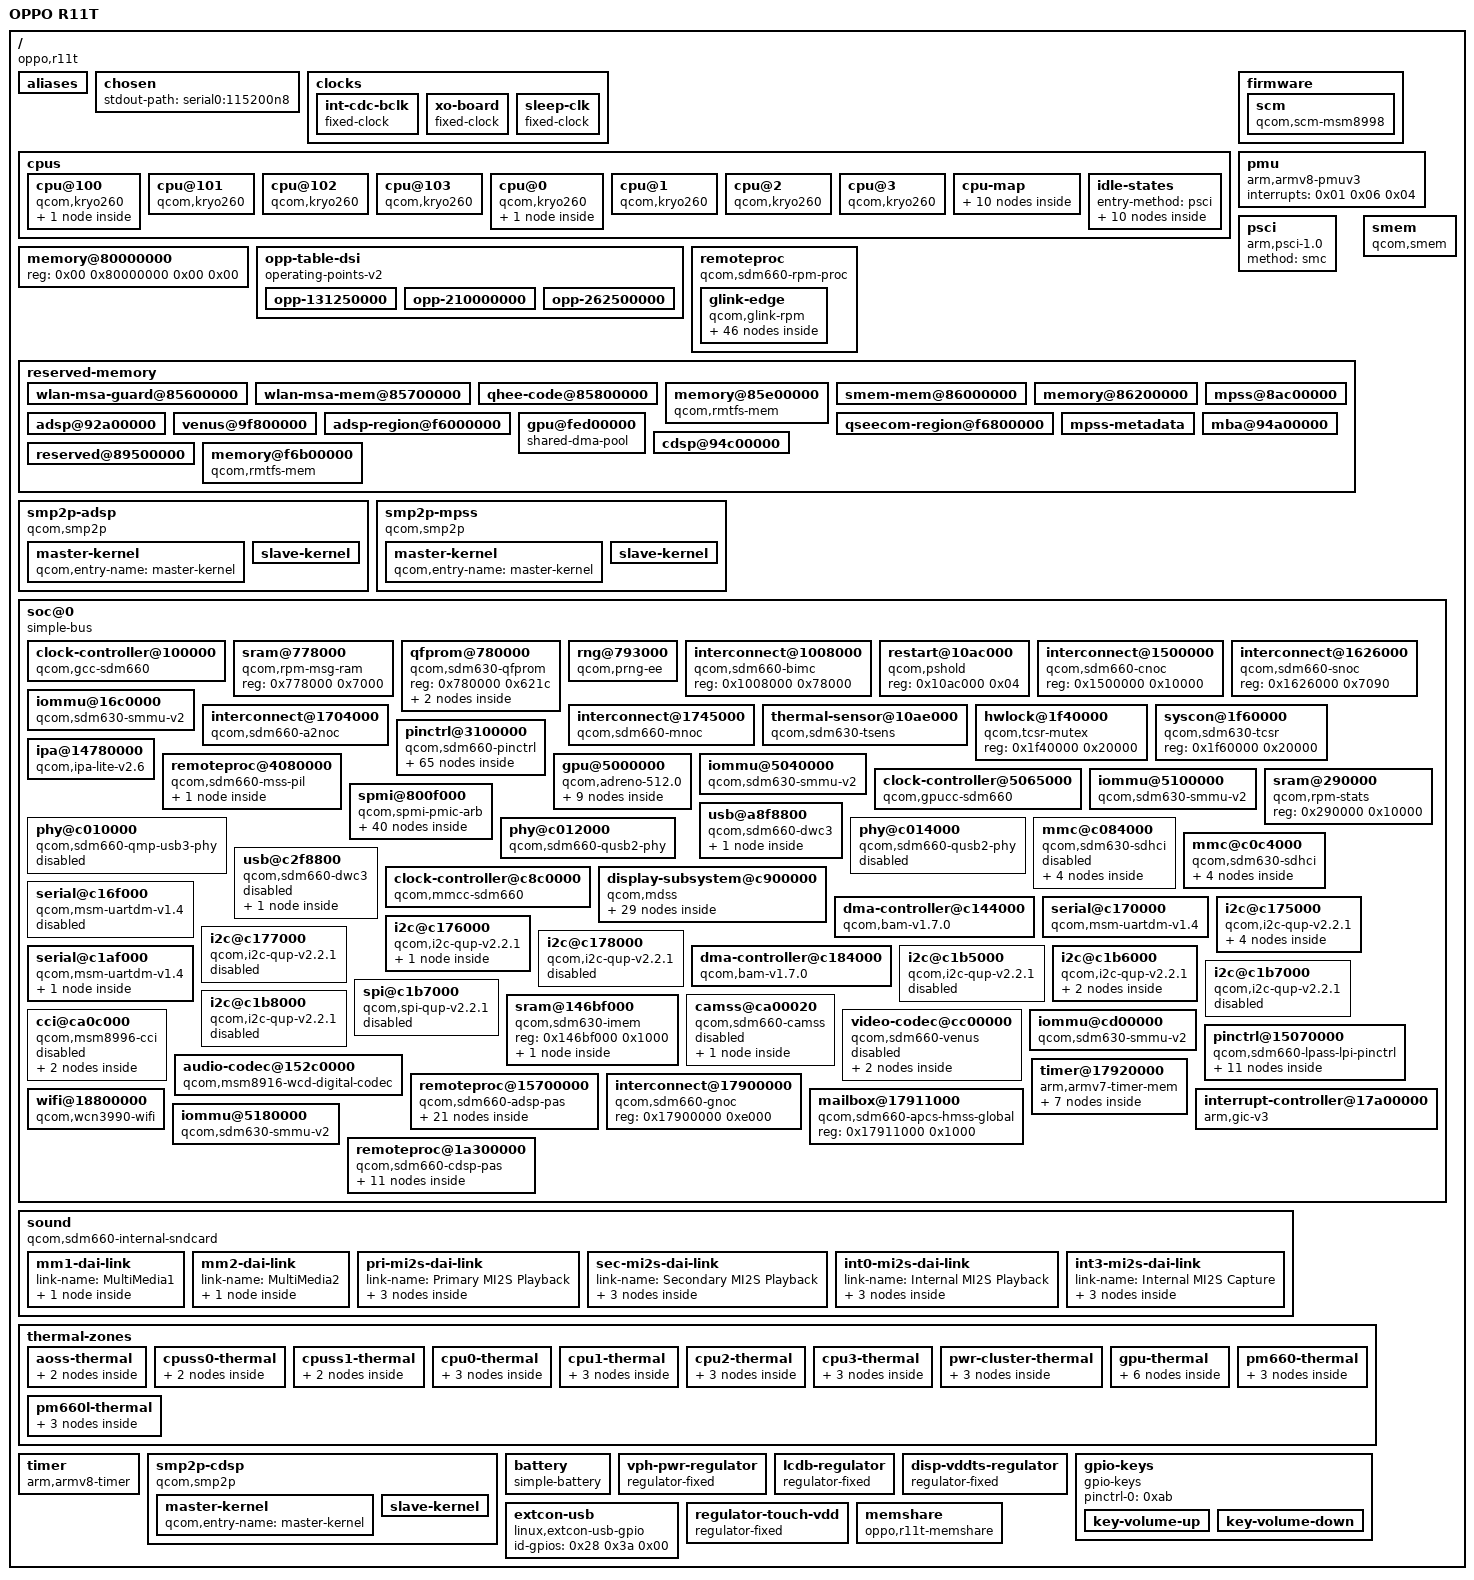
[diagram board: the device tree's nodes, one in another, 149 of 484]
/dts-v1/;

/ {
	interrupt-parent = <0x01>;
	#address-cells = <0x02>;
	#size-cells = <0x02>;
	model = "OPPO R11T";
	compatible = "oppo,r11t", "qcom,sdm660";
	chassis-type = "handset";
	qcom,msm-id = <0x13d 0x00>;
	qcom,board-id = <0x08 0x00 0x3eb3>;
	qcom,pmic-id = <0x1001b 0x1011a 0x00 0x00 0x1001b 0x2001a 0x00 0x00 0x1001b 0x202001a 0x00 0x00>;

	aliases {
		mmc1 = "/soc@0/mmc@c0c4000";
		mmc2 = "/soc@0/mmc@c084000";
		serial0 = "/soc@0/serial@c170000";
		serial1 = "/soc@0/serial@c1af000";
	};

	chosen {
		#address-cells = <0x02>;
		#size-cells = <0x02>;
		ranges;
		stdout-path = "serial0:115200n8";
	};

	clocks {

		int-cdc-bclk {
			compatible = "fixed-clock";
			#clock-cells = <0x00>;
			clock-frequency = <0x177000>;
			clock-output-names = "int_cdc_bclk";
			phandle = <0x8f>;
		};

		xo-board {
			compatible = "fixed-clock";
			#clock-cells = <0x00>;
			clock-frequency = <0x124f800>;
			clock-output-names = "xo_board";
			phandle = <0x23>;
		};

		sleep-clk {
			compatible = "fixed-clock";
			#clock-cells = <0x00>;
			clock-frequency = <0x7ffc>;
			clock-output-names = "sleep_clk";
			phandle = <0x24>;
		};
	};

	cpus {
		#address-cells = <0x02>;
		#size-cells = <0x00>;

		cpu@100 {
			device_type = "cpu";
			compatible = "qcom,kryo260";
			reg = <0x00 0x100>;
			enable-method = "psci";
			cpu-idle-states = <0x02 0x03 0x04 0x05 0x06>;
			capacity-dmips-mhz = <0x400>;
			#cooling-cells = <0x02>;
			next-level-cache = <0x07>;
			phandle = <0x12>;

			l2-cache {
				compatible = "cache";
				cache-level = <0x02>;
				cache-unified;
				phandle = <0x07>;
			};
		};

		cpu@101 {
			device_type = "cpu";
			compatible = "qcom,kryo260";
			reg = <0x00 0x101>;
			enable-method = "psci";
			cpu-idle-states = <0x02 0x03 0x04 0x05 0x06>;
			capacity-dmips-mhz = <0x400>;
			#cooling-cells = <0x02>;
			next-level-cache = <0x07>;
			phandle = <0x13>;
		};

		cpu@102 {
			device_type = "cpu";
			compatible = "qcom,kryo260";
			reg = <0x00 0x102>;
			enable-method = "psci";
			cpu-idle-states = <0x02 0x03 0x04 0x05 0x06>;
			capacity-dmips-mhz = <0x400>;
			#cooling-cells = <0x02>;
			next-level-cache = <0x07>;
			phandle = <0x14>;
		};

		cpu@103 {
			device_type = "cpu";
			compatible = "qcom,kryo260";
			reg = <0x00 0x103>;
			enable-method = "psci";
			cpu-idle-states = <0x02 0x03 0x04 0x05 0x06>;
			capacity-dmips-mhz = <0x400>;
			#cooling-cells = <0x02>;
			next-level-cache = <0x07>;
			phandle = <0x15>;
		};

		cpu@0 {
			device_type = "cpu";
			compatible = "qcom,kryo260";
			reg = <0x00 0x00>;
			enable-method = "psci";
			cpu-idle-states = <0x08 0x09 0x0a 0x0b 0x0c>;
			capacity-dmips-mhz = <0x280>;
			#cooling-cells = <0x02>;
			next-level-cache = <0x0d>;
			phandle = <0x0e>;

			l2-cache {
				compatible = "cache";
				cache-level = <0x02>;
				cache-unified;
				phandle = <0x0d>;
			};
		};

		cpu@1 {
			device_type = "cpu";
			compatible = "qcom,kryo260";
			reg = <0x00 0x01>;
			enable-method = "psci";
			cpu-idle-states = <0x08 0x09 0x0a 0x0b 0x0c>;
			capacity-dmips-mhz = <0x280>;
			#cooling-cells = <0x02>;
			next-level-cache = <0x0d>;
			phandle = <0x0f>;
		};

		cpu@2 {
			device_type = "cpu";
			compatible = "qcom,kryo260";
			reg = <0x00 0x02>;
			enable-method = "psci";
			cpu-idle-states = <0x08 0x09 0x0a 0x0b 0x0c>;
			capacity-dmips-mhz = <0x280>;
			#cooling-cells = <0x02>;
			next-level-cache = <0x0d>;
			phandle = <0x10>;
		};

		cpu@3 {
			device_type = "cpu";
			compatible = "qcom,kryo260";
			reg = <0x00 0x03>;
			enable-method = "psci";
			cpu-idle-states = <0x08 0x09 0x0a 0x0b 0x0c>;
			capacity-dmips-mhz = <0x280>;
			#cooling-cells = <0x02>;
			next-level-cache = <0x0d>;
			phandle = <0x11>;
		};

		cpu-map {

			cluster0 {

				core0 {
					cpu = <0x0e>;
				};

				core1 {
					cpu = <0x0f>;
				};

				core2 {
					cpu = <0x10>;
				};

				core3 {
					cpu = <0x11>;
				};
			};

			cluster1 {

				core0 {
					cpu = <0x12>;
				};

				core1 {
					cpu = <0x13>;
				};

				core2 {
					cpu = <0x14>;
				};

				core3 {
					cpu = <0x15>;
				};
			};
		};

		idle-states {
			entry-method = "psci";

			cpu-sleep-0-0 {
				compatible = "arm,idle-state";
				idle-state-name = "pwr-retention";
				arm,psci-suspend-param = <0x40000002>;
				entry-latency-us = <0x152>;
				exit-latency-us = <0x1a7>;
				min-residency-us = <0xc8>;
				phandle = <0x08>;
			};

			cpu-sleep-0-1 {
				compatible = "arm,idle-state";
				idle-state-name = "pwr-power-collapse";
				arm,psci-suspend-param = <0x40000003>;
				entry-latency-us = <0x203>;
				exit-latency-us = <0x71d>;
				min-residency-us = <0x3e8>;
				local-timer-stop;
				phandle = <0x09>;
			};

			cpu-sleep-1-0 {
				compatible = "arm,idle-state";
				idle-state-name = "perf-retention";
				arm,psci-suspend-param = <0x40000002>;
				entry-latency-us = <0x9a>;
				exit-latency-us = <0x57>;
				min-residency-us = <0xc8>;
				phandle = <0x02>;
			};

			cpu-sleep-1-1 {
				compatible = "arm,idle-state";
				idle-state-name = "perf-power-collapse";
				arm,psci-suspend-param = <0x40000003>;
				entry-latency-us = <0x106>;
				exit-latency-us = <0x12d>;
				min-residency-us = <0x3e8>;
				local-timer-stop;
				phandle = <0x03>;
			};

			cluster-sleep-0-0 {
				compatible = "arm,idle-state";
				idle-state-name = "pwr-cluster-dynamic-retention";
				arm,psci-suspend-param = <0x400000f2>;
				entry-latency-us = <0x11c>;
				exit-latency-us = <0x180>;
				min-residency-us = <0x2703>;
				local-timer-stop;
				phandle = <0x0a>;
			};

			cluster-sleep-0-1 {
				compatible = "arm,idle-state";
				idle-state-name = "pwr-cluster-retention";
				arm,psci-suspend-param = <0x400000f3>;
				entry-latency-us = <0x152>;
				exit-latency-us = <0x1a7>;
				min-residency-us = <0x2703>;
				local-timer-stop;
				phandle = <0x0b>;
			};

			cluster-sleep-0-2 {
				compatible = "arm,idle-state";
				idle-state-name = "pwr-cluster-retention";
				arm,psci-suspend-param = <0x400000f4>;
				entry-latency-us = <0x203>;
				exit-latency-us = <0x71d>;
				min-residency-us = <0x2703>;
				local-timer-stop;
				phandle = <0x0c>;
			};

			cluster-sleep-1-0 {
				compatible = "arm,idle-state";
				idle-state-name = "perf-cluster-dynamic-retention";
				arm,psci-suspend-param = <0x400000f2>;
				entry-latency-us = <0x110>;
				exit-latency-us = <0x149>;
				min-residency-us = <0x2703>;
				local-timer-stop;
				phandle = <0x04>;
			};

			cluster-sleep-1-1 {
				compatible = "arm,idle-state";
				idle-state-name = "perf-cluster-retention";
				arm,psci-suspend-param = <0x400000f3>;
				entry-latency-us = <0x14c>;
				exit-latency-us = <0x170>;
				min-residency-us = <0x2703>;
				local-timer-stop;
				phandle = <0x05>;
			};

			cluster-sleep-1-2 {
				compatible = "arm,idle-state";
				idle-state-name = "perf-cluster-retention";
				arm,psci-suspend-param = <0x400000f4>;
				entry-latency-us = <0x221>;
				exit-latency-us = <0x649>;
				min-residency-us = <0x2703>;
				local-timer-stop;
				phandle = <0x06>;
			};
		};
	};

	firmware {

		scm {
			compatible = "qcom,scm-msm8998", "qcom,scm";
		};
	};

	memory@80000000 {
		device_type = "memory";
		reg = <0x00 0x80000000 0x00 0x00>;
	};

	opp-table-dsi {
		compatible = "operating-points-v2";
		phandle = <0x5b>;

		opp-131250000 {
			opp-hz = <0x00 0x7d2b750>;
			required-opps = <0x16>;
		};

		opp-210000000 {
			opp-hz = <0x00 0xc845880>;
			required-opps = <0x17>;
		};

		opp-262500000 {
			opp-hz = <0x00 0xfa56ea0>;
			required-opps = <0x18>;
		};
	};

	pmu {
		compatible = "arm,armv8-pmuv3";
		interrupts = <0x01 0x06 0x04>;
	};

	psci {
		compatible = "arm,psci-1.0";
		method = "smc";
	};

	remoteproc {
		compatible = "qcom,sdm660-rpm-proc", "qcom,rpm-proc";

		glink-edge {
			compatible = "qcom,glink-rpm";
			interrupts = <0x00 0xa8 0x01>;
			qcom,rpm-msg-ram = <0x19>;
			mboxes = <0x1a 0x00>;

			rpm-requests {
				compatible = "qcom,rpm-sdm660", "qcom,glink-smd-rpm";
				qcom,glink-channels = "rpm_requests";

				clock-controller {
					compatible = "qcom,rpmcc-sdm660", "qcom,rpmcc";
					#clock-cells = <0x01>;
					phandle = <0x26>;
				};

				power-controller {
					compatible = "qcom,sdm660-rpmpd";
					#power-domain-cells = <0x01>;
					operating-points-v2 = <0x1b>;
					phandle = <0x32>;

					opp-table {
						compatible = "operating-points-v2";
						phandle = <0x1b>;

						opp1 {
							opp-level = <0x10>;
						};

						opp2 {
							opp-level = <0x20>;
						};

						opp3 {
							opp-level = <0x30>;
						};

						opp4 {
							opp-level = <0x40>;
							phandle = <0x4b>;
						};

						opp5 {
							opp-level = <0x80>;
							phandle = <0x16>;
						};

						opp6 {
							opp-level = <0xc0>;
							phandle = <0x17>;
						};

						opp7 {
							opp-level = <0x100>;
							phandle = <0x18>;
						};

						opp8 {
							opp-level = <0x140>;
						};

						opp9 {
							opp-level = <0x180>;
							phandle = <0x5a>;
						};
					};
				};

				regulators-0 {
					compatible = "qcom,rpm-pm660l-regulators";
					vdd_s1-supply = <0x1c>;
					vdd_s2-supply = <0x1c>;
					vdd_s3_s4-supply = <0x1c>;
					vdd_s5-supply = <0x1c>;
					vdd_s6-supply = <0x1c>;
					vdd_l1_l9_l10-supply = <0x1d>;
					vdd_l2-supply = <0x1e>;
					vdd_l3_l5_l7_l8-supply = <0x1e>;
					vdd_l4_l6-supply = <0x1e>;
					vdd_bob-supply = <0x1c>;

					bob {
						regulator-min-microvolt = <0x325aa0>;
						regulator-max-microvolt = <0x36ee80>;
						regulator-enable-ramp-delay = <0x1f4>;
						phandle = <0x1e>;
					};

					s1 {
						regulator-min-microvolt = <0x112a88>;
						regulator-max-microvolt = <0x112a88>;
						regulator-enable-ramp-delay = <0xc8>;
					};

					s2 {
						regulator-min-microvolt = <0x100590>;
						regulator-max-microvolt = <0x100590>;
						regulator-enable-ramp-delay = <0xc8>;
						phandle = <0x1d>;
					};

					l1 {
						regulator-min-microvolt = "", "\f5";
						regulator-max-microvolt = <0xe1d48>;
						regulator-enable-ramp-delay = <0xfa>;
						regulator-allow-set-load;
						phandle = <0x44>;
					};

					l2 {
						regulator-min-microvolt = <0x192580>;
						regulator-max-microvolt = <0x292340>;
						regulator-enable-ramp-delay = <0xfa>;
						regulator-allow-set-load;
					};

					l3 {
						regulator-min-microvolt = <0x19f0a0>;
						regulator-max-microvolt = <0x325aa0>;
						regulator-enable-ramp-delay = <0xfa>;
						regulator-allow-set-load;
						regulator-always-on;
					};

					l4 {
						regulator-min-microvolt = <0x2cec00>;
						regulator-max-microvolt = <0x2d0b40>;
						regulator-enable-ramp-delay = <0xfa>;
						regulator-min-microamp = <0xc8>;
						regulator-max-microamp = <0x927c0>;
						regulator-system-load = <0x8b290>;
						regulator-allow-set-load;
						phandle = <0x4f>;
					};

					l5 {
						regulator-min-microvolt = <0x1b7740>;
						regulator-max-microvolt = <0x32c800>;
						regulator-enable-ramp-delay = <0xfa>;
						regulator-allow-set-load;
						regulator-system-load = "", "\f5";
					};

					l7 {
						regulator-min-microvolt = <0x2932e0>;
						regulator-max-microvolt = <0x2faf08>;
						regulator-enable-ramp-delay = <0xfa>;
						phandle = <0x46>;
					};

					l8 {
						regulator-min-microvolt = <0x30d400>;
						regulator-max-microvolt = <0x33e140>;
						regulator-enable-ramp-delay = <0xfa>;
					};

					l6 {
						regulator-min-microvolt = <0x2dc6c0>;
						regulator-max-microvolt = <0x2dc6c0>;
						regulator-enable-ramp-delay = <0xfa>;
						regulator-system-load = <0x3390>;
						regulator-allow-set-load;
						phandle = <0x60>;
					};
				};

				regulators-1 {
					compatible = "qcom,rpm-pm660-regulators";
					vdd_s1-supply = <0x1c>;
					vdd_s2-supply = <0x1c>;
					vdd_s3-supply = <0x1c>;
					vdd_s4-supply = <0x1c>;
					vdd_s5-supply = <0x1c>;
					vdd_s6-supply = <0x1c>;
					vdd_l1_l6_l7-supply = <0x1f>;
					vdd_l2_l3-supply = <0x1d>;
					vdd_l5-supply = <0x1d>;
					vdd_l8_l9_l10_l11_l12_l13_l14-supply = <0x20>;
					vdd_l15_l16_l17_l18_l19-supply = <0x1e>;

					s4 {
						regulator-min-microvolt = <0x1b8ac8>;
						regulator-max-microvolt = <0x1f20c0>;
						regulator-enable-ramp-delay = <0xc8>;
						regulator-always-on;
						phandle = <0x20>;
					};

					s5 {
						regulator-min-microvolt = <0x12ad40>;
						regulator-max-microvolt = <0x149970>;
						regulator-enable-ramp-delay = <0xc8>;
						phandle = <0x1f>;
					};

					s6 {
						regulator-min-microvolt = <0x7b0c0>;
						regulator-max-microvolt = <0xf2300>;
						regulator-enable-ramp-delay = <0x96>;
					};

					l1 {
						regulator-min-microvolt = <0x118c30>;
						regulator-max-microvolt = <0x1312d0>;
						regulator-enable-ramp-delay = <0xfa>;
						regulator-allow-set-load;
						phandle = <0x5c>;
					};

					l2 {
						regulator-min-microvolt = <0xe7ef0>;
						regulator-max-microvolt = <0xf6950>;
						regulator-enable-ramp-delay = <0xfa>;
					};

					l3 {
						regulator-min-microvolt = <0xe7ef0>;
						regulator-max-microvolt = <0xf6950>;
						regulator-enable-ramp-delay = <0xfa>;
					};

					l5 {
						regulator-min-microvolt = <0x802c8>;
						regulator-max-microvolt = <0xe7ef0>;
						regulator-enable-ramp-delay = <0xfa>;
						phandle = <0x96>;
					};

					l6 {
						regulator-min-microvolt = <0x124f80>;
						regulator-max-microvolt = <0x14e790>;
						regulator-allow-set-load;
						regulator-enable-ramp-delay = <0xfa>;
						phandle = <0x7e>;
					};

					l7 {
						regulator-min-microvolt = <0x124f80>;
						regulator-max-microvolt = <0x124f80>;
						regulator-enable-ramp-delay = <0xfa>;
					};

					l8 {
						regulator-min-microvolt = <0x1ab3f0>;
						regulator-max-microvolt = <0x1b7740>;
						regulator-enable-ramp-delay = <0xfa>;
						regulator-system-load = <0x4f588>;
						regulator-allow-set-load;
						phandle = <0x50>;
					};

					l9 {
						regulator-min-microvolt = <0x1ab3f0>;
						regulator-max-microvolt = <0x1cfde0>;
						regulator-enable-ramp-delay = <0xfa>;
						regulator-allow-set-load;
						phandle = <0x7d>;
					};

					l10 {
						regulator-min-microvolt = <0x1b2920>;
						regulator-max-microvolt = <0x1dc130>;
						regulator-enable-ramp-delay = <0xfa>;
						regulator-allow-set-load;
						regulator-system-load = <0x36b0>;
						phandle = <0x45>;
					};

					l11 {
						regulator-min-microvolt = <0x1b2920>;
						regulator-max-microvolt = <0x1dc130>;
						regulator-enable-ramp-delay = <0xfa>;
						phandle = <0x5f>;
					};

					l12 {
						regulator-min-microvolt = <0x1b2920>;
						regulator-max-microvolt = <0x1dc130>;
						regulator-enable-ramp-delay = <0xfa>;
					};

					l13 {
						regulator-min-microvolt = <0x1b2920>;
						regulator-max-microvolt = <0x1dc130>;
						regulator-enable-ramp-delay = <0xfa>;
						regulator-boot-on;
						regulator-always-on;
						phandle = <0x80>;
					};

					l14 {
						regulator-min-microvolt = <0x1a17b0>;
						regulator-max-microvolt = <0x1cfde0>;
						regulator-enable-ramp-delay = <0xfa>;
						phandle = <0x73>;
					};

					l15 {
						regulator-min-microvolt = <0x192d50>;
						regulator-max-microvolt = <0x2d0370>;
						regulator-enable-ramp-delay = <0xfa>;
					};

					l16 {
						regulator-min-microvolt = <0x2ab980>;
						regulator-max-microvolt = <0x2ab980>;
						regulator-enable-ramp-delay = <0xfa>;
						regulator-always-on;
					};

					l17 {
						regulator-min-microvolt = <0x192580>;
						regulator-max-microvolt = <0x2d0b40>;
						regulator-enable-ramp-delay = <0xfa>;
					};

					l19 {
						regulator-min-microvolt = <0x328980>;
						regulator-max-microvolt = <0x33e140>;
						regulator-enable-ramp-delay = <0xfa>;
						regulator-allow-set-load;
						phandle = <0x7f>;
					};
				};
			};
		};
	};

	reserved-memory {
		#address-cells = <0x02>;
		#size-cells = <0x02>;
		ranges;

		wlan-msa-guard@85600000 {
			reg = <0x00 0x85600000 0x00 0x100000>;
			no-map;
		};

		wlan-msa-mem@85700000 {
			reg = <0x00 0x85700000 0x00 0x100000>;
			no-map;
			phandle = <0x95>;
		};

		qhee-code@85800000 {
			reg = <0x00 0x85800000 0x00 0x600000>;
			no-map;
		};

		memory@85e00000 {
			compatible = "qcom,rmtfs-mem";
			reg = <0x00 0x85e00000 0x00 0x200000>;
			no-map;
			qcom,client-id = <0x01>;
			qcom,vmid = <0x0f>;
		};

		smem-mem@86000000 {
			reg = <0x00 0x86000000 0x00 0x200000>;
			no-map;
			phandle = <0x21>;
		};

		memory@86200000 {
			reg = <0x00 0x86200000 0x00 0x3300000>;
			no-map;
		};

		mpss@8ac00000 {
			reg = <0x00 0x8ac00000 0x00 0x7e00000>;
			no-map;
			phandle = <0x34>;
		};

		adsp@92a00000 {
			reg = <0x00 0x92a00000 0x00 0x2000000>;
			no-map;
			phandle = <0x92>;
		};

		venus@9f800000 {
			reg = <0x00 0x9f800000 0x00 0x800000>;
			no-map;
			phandle = <0x8d>;
		};

		adsp-region@f6000000 {
			reg = <0x00 0xf6000000 0x00 0x800000>;
			no-map;
		};

		qseecom-region@f6800000 {
			reg = <0x00 0xf6800000 0x00 0x1400000>;
			no-map;
		};

		gpu@fed00000 {
			compatible = "shared-dma-pool";
			reg = <0x00 0xfed00000 0x00 0xa00000>;
			no-map;
			phandle = <0x3a>;
		};

		mpss-metadata {
			alloc-ranges = <0x00 0xa0000000 0x00 0x20000000>;
			size = <0x00 0x4000>;
			no-map;
			phandle = <0x35>;
		};


		mba@94a00000 {
			reg = <0x00 0x94a00000 0x00 0x200000>;
			no-map;
			phandle = <0x33>;
		};

		cdsp@94c00000 {
			reg = <0x00 0x94c00000 0x00 0x600000>;
			no-map;
			phandle = <0x98>;
		};

		reserved@89500000 {
			reg = <0x00 0x89500000 0x00 0x1700000>;
			no-map;
		};

		memory@f6b00000 {
			compatible = "qcom,rmtfs-mem";
			reg = <0x00 0xf6b00000 0x00 0x100000>;
			no-map;
			qcom,client-id = <0x04>;
			qcom,vmid = <0x0f>;
		};
	};

	smem {
		compatible = "qcom,smem";
		memory-region = <0x21>;
		hwlocks = <0x22 0x03>;
	};

	smp2p-adsp {
		compatible = "qcom,smp2p";
		qcom,smem = <0x1bb 0x1ad>;
		interrupts = <0x00 0x9e 0x01>;
		mboxes = <0x1a 0x0a>;
		qcom,local-pid = <0x00>;
		qcom,remote-pid = <0x02>;

		master-kernel {
			qcom,entry-name = "master-kernel";
			#qcom,smem-state-cells = <0x01>;
			phandle = <0x93>;
		};

		slave-kernel {
			qcom,entry-name = "slave-kernel";
			interrupt-controller;
			#interrupt-cells = <0x02>;
			phandle = <0x91>;
		};
	};

	smp2p-mpss {
		compatible = "qcom,smp2p";
		qcom,smem = <0x1b3 0x1ac>;
		interrupts = <0x00 0x1c3 0x01>;
		mboxes = <0x1a 0x0e>;
		qcom,local-pid = <0x00>;
		qcom,remote-pid = <0x01>;

		master-kernel {
			qcom,entry-name = "master-kernel";
			#qcom,smem-state-cells = <0x01>;
			phandle = <0x30>;
		};

		slave-kernel {
			qcom,entry-name = "slave-kernel";
			interrupt-controller;
			#interrupt-cells = <0x02>;
			phandle = <0x2f>;
		};
	};

	soc@0 {
		#address-cells = <0x01>;
		#size-cells = <0x01>;
		ranges = <0x00 0x00 0x00 0xffffffff>;
		compatible = "simple-bus";

		clock-controller@100000 {
			compatible = "qcom,gcc-sdm660";
			#clock-cells = <0x01>;
			#reset-cells = <0x01>;
			#power-domain-cells = <0x01>;
			reg = <0x100000 0x94000>;
			clock-names = "xo", "sleep_clk";
			clocks = <0x23 0x24>;
			phandle = <0x25>;
		};

		sram@778000 {
			compatible = "qcom,rpm-msg-ram";
			reg = <0x778000 0x7000>;
			phandle = <0x19>;
		};

		qfprom@780000 {
			compatible = "qcom,sdm630-qfprom", "qcom,qfprom";
			reg = <0x780000 0x621c>;
			#address-cells = <0x01>;
			#size-cells = <0x01>;

			hstx-trim@240 {
				reg = <0x243 0x01>;
				bits = <0x01 0x03>;
				phandle = <0x43>;
			};

			gpu-speed-bin@41a0 {
				reg = <0x41a2 0x02>;
				bits = <0x05 0x08>;
				phandle = <0x38>;
			};
		};

		rng@793000 {
			compatible = "qcom,prng-ee";
			reg = <0x793000 0x1000>;
			clocks = <0x25 0x47>;
			clock-names = "core";
		};

		interconnect@1008000 {
			compatible = "qcom,sdm660-bimc";
			reg = <0x1008000 0x78000>;
			#interconnect-cells = <0x01>;
			phandle = <0x2a>;
		};

		restart@10ac000 {
			compatible = "qcom,pshold";
			reg = <0x10ac000 0x04>;
		};

		interconnect@1500000 {
			compatible = "qcom,sdm660-cnoc";
			reg = <0x1500000 0x10000>;
			#interconnect-cells = <0x01>;
			phandle = <0x47>;
		};

		interconnect@1626000 {
			compatible = "qcom,sdm660-snoc";
			reg = <0x1626000 0x7090>;
			#interconnect-cells = <0x01>;
			phandle = <0x2b>;
		};

		iommu@16c0000 {
			compatible = "qcom,sdm630-smmu-v2", "qcom,smmu-v2";
			reg = <0x16c0000 0x40000>;
			#global-interrupts = <0x02>;
			#iommu-cells = <0x01>;
			interrupts = <0x00 0xe5 0x04 0x00 0xe7 0x04 0x00 0x175 0x04 0x00 0x176 0x08 0x00 0x177 0x08 0x00 0x178 0x08 0x00 0x179 0x08 0x00 0x17a 0x08 0x00 0x1ce 0x04 0x00 0x1cf 0x04 0x00 0x1d0 0x04 0x00 0x1d1 0x04 0x00 0x1d2 0x04 0x00 0x1d3 0x04 0x00 0x161 0x04 0x00 0x162 0x04 0x00 0x163 0x04 0x00 0x164 0x04 0x00 0x165 0x04 0x00 0x166 0x04 0x00 0x167 0x04 0x00 0x168 0x04 0x00 0x1ba 0x04 0x00 0x1bb 0x04 0x00 0x1bc 0x04 0x00 0x1bf 0x04 0x00 0x1d4 0x04 0x00 0x1d5 0x04 0x00 0x1d8 0x04 0x00 0x1d9 0x04 0x00 0x1da 0x04>;
			phandle = <0x2d>;
		};

		interconnect@1704000 {
			compatible = "qcom,sdm660-a2noc";
			reg = <0x1704000 0xc100>;
			#interconnect-cells = <0x01>;
			clock-names = "ipa", "ufs_axi", "aggre2_ufs_axi", "aggre2_usb3_axi", "cfg_noc_usb2_axi";
			clocks = <0x26 0x44 0x25 0x50 0x25 0x14 0x25 0x15 0x25 0x30>;
			phandle = <0x29>;
		};

		interconnect@1745000 {
			compatible = "qcom,sdm660-mnoc";
			reg = <0x1745000 0xa010>;
			#interconnect-cells = <0x01>;
			clock-names = "iface";
			clocks = <0x27 0x00>;
			phandle = <0x55>;
		};

		thermal-sensor@10ae000 {
			compatible = "qcom,sdm630-tsens", "qcom,tsens-v2";
			reg = <0x10ae000 0x1000 0x10ad000 0x1000>;
			#qcom,sensors = <0x0e>;
			interrupts = <0x00 0xb8 0x04 0x00 0x1ae 0x04>;
			interrupt-names = "uplow", "critical";
			#thermal-sensor-cells = <0x01>;
			phandle = <0xa6>;
		};

		hwlock@1f40000 {
			compatible = "qcom,tcsr-mutex";
			reg = <0x1f40000 0x20000>;
			#hwlock-cells = <0x01>;
			phandle = <0x22>;
		};

		syscon@1f60000 {
			compatible = "qcom,sdm630-tcsr", "syscon";
			reg = <0x1f60000 0x20000>;
			phandle = <0x31>;
		};

		pinctrl@3100000 {
			compatible = "qcom,sdm660-pinctrl";
			reg = <0x3100000 0x400000 0x3500000 0x400000 0x3900000 0x400000>;
			reg-names = "south", "center", "north";
			interrupts = <0x00 0xd0 0x04>;
			gpio-controller;
			gpio-ranges = <0x28 0x00 0x00 0x72>;
			#gpio-cells = <0x02>;
			interrupt-controller;
			#interrupt-cells = <0x02>;
			gpio-reserved-ranges = <0x08 0x04>;
			phandle = <0x28>;

			blsp1-uart1-default-state {
				pins = "gpio0", "gpio1", "gpio2", "gpio3";
				function = "blsp_uart1";
				drive-strength = <0x02>;
				bias-disable;
				phandle = <0x69>;
			};

			blsp1-uart1-sleep-state {
				pins = "gpio0", "gpio1", "gpio2", "gpio3";
				function = "gpio";
				drive-strength = <0x02>;
				bias-disable;
				phandle = <0x6a>;
			};

			blsp1-uart2-default-state {
				pins = "gpio4", "gpio5";
				function = "blsp_uart2";
				drive-strength = <0x02>;
				bias-disable;
				phandle = <0x6b>;
			};

			blsp2-uart1-active-state {
				phandle = <0x7b>;

				tx-rts-pins {
					pins = "gpio16", "gpio19";
					function = "blsp_uart5";
					drive-strength = <0x02>;
					bias-disable;
				};

				rx-pins {
					pins = "gpio17";
					function = "blsp_uart5";
					drive-strength = <0x02>;
					bias-pull-up;
				};

				cts-pins {
					pins = "gpio18";
					function = "blsp_uart5";
					drive-strength = <0x02>;
					bias-pull-down;
				};
			};

			blsp2-uart1-sleep-state {
				phandle = <0x7c>;

				tx-pins {
					pins = "gpio16";
					function = "gpio";
					drive-strength = <0x02>;
					bias-pull-up;
				};

				rx-cts-rts-pins {
					pins = "gpio17", "gpio18", "gpio19";
					function = "gpio";
					drive-strength = <0x02>;
					bias-disable;
				};
			};

			i2c1-default-state {
				pins = "gpio2", "gpio3";
				function = "blsp_i2c1";
				drive-strength = <0x02>;
				bias-disable;
				phandle = <0x6c>;
			};

			i2c1-sleep-state {
				pins = "gpio2", "gpio3";
				function = "blsp_i2c1";
				drive-strength = <0x02>;
				bias-pull-up;
				phandle = <0x6d>;
			};

			i2c2-default-state {
				pins = "gpio6", "gpio7";
				function = "blsp_i2c2";
				drive-strength = <0x02>;
				bias-disable;
				phandle = <0x74>;
			};

			i2c2-sleep-state {
				pins = "gpio6", "gpio7";
				function = "blsp_i2c2";
				drive-strength = <0x02>;
				bias-pull-up;
				phandle = <0x75>;
			};

			i2c3-default-state {
				pins = "gpio10", "gpio11";
				function = "blsp_i2c3";
				drive-strength = <0x02>;
				bias-disable;
				phandle = <0x76>;
			};

			i2c3-sleep-state {
				pins = "gpio10", "gpio11";
				function = "blsp_i2c3";
				drive-strength = <0x02>;
				bias-pull-up;
				phandle = <0x77>;
			};

			i2c4-default-state {
				pins = "gpio14", "gpio15";
				function = "blsp_i2c4";
				drive-strength = <0x02>;
				bias-disable;
				phandle = <0x78>;
			};

			i2c4-sleep-state {
				pins = "gpio14", "gpio15";
				function = "blsp_i2c4";
				drive-strength = <0x02>;
				bias-pull-up;
				phandle = <0x79>;
			};

			i2c5-default-state {
				pins = "gpio18", "gpio19";
				function = "blsp_i2c5";
				drive-strength = <0x02>;
				bias-disable;
				phandle = <0x81>;
			};

			i2c5-sleep-state {
				pins = "gpio18", "gpio19";
				function = "blsp_i2c5";
				drive-strength = <0x02>;
				bias-pull-up;
				phandle = <0x82>;
			};

			i2c6-default-state {
				pins = "gpio22", "gpio23";
				function = "blsp_i2c6";
				drive-strength = <0x02>;
				bias-disable;
				phandle = <0x83>;
			};

			i2c6-sleep-state {
				pins = "gpio22", "gpio23";
				function = "blsp_i2c6";
				drive-strength = <0x02>;
				bias-pull-up;
				phandle = <0x84>;
			};

			i2c7-default-state {
				pins = "gpio26", "gpio27";
				function = "blsp_i2c7";
				drive-strength = <0x02>;
				bias-disable;
				phandle = <0x85>;
			};

			i2c7-sleep-state {
				pins = "gpio26", "gpio27";
				function = "blsp_i2c7";
				drive-strength = <0x02>;
				bias-pull-up;
				phandle = <0x86>;
			};

			i2c8-default-state {
				pins = "gpio30", "gpio31";
				function = "blsp_i2c8_a";
				drive-strength = <0x02>;
				bias-disable;
				phandle = <0x89>;
			};

			i2c8-sleep-state {
				pins = "gpio30", "gpio31";
				function = "blsp_i2c8_a";
				drive-strength = <0x02>;
				bias-pull-up;
				phandle = <0x8a>;
			};

			cci0-default-state {
				pins = "gpio36", "gpio37";
				function = "cci_i2c";
				bias-pull-up;
				drive-strength = <0x02>;
				phandle = <0x8b>;
			};

			cci1-default-state {
				pins = "gpio38", "gpio39";
				function = "cci_i2c";
				bias-pull-up;
				drive-strength = <0x02>;
				phandle = <0x8c>;
			};

			sdc1-on-state {
				phandle = <0x4d>;

				clk-pins {
					pins = "sdc1_clk";
					bias-disable;
					drive-strength = <0x10>;
				};

				cmd-pins {
					pins = "sdc1_cmd";
					bias-pull-up;
					drive-strength = <0x0a>;
				};

				data-pins {
					pins = "sdc1_data";
					bias-pull-up;
					drive-strength = <0x0a>;
				};

				rclk-pins {
					pins = "sdc1_rclk";
					bias-pull-down;
				};
			};

			sdc1-off-state {
				phandle = <0x4e>;

				clk-pins {
					pins = "sdc1_clk";
					bias-disable;
					drive-strength = <0x02>;
				};

				cmd-pins {
					pins = "sdc1_cmd";
					bias-pull-up;
					drive-strength = <0x02>;
				};

				data-pins {
					pins = "sdc1_data";
					bias-pull-up;
					drive-strength = <0x02>;
				};

				rclk-pins {
					pins = "sdc1_rclk";
					bias-pull-down;
				};
			};

			sdc2-on-state {
				phandle = <0x49>;

				clk-pins {
					pins = "sdc2_clk";
					bias-disable;
					drive-strength = <0x10>;
				};

				cmd-pins {
					pins = "sdc2_cmd";
					bias-pull-up;
					drive-strength = <0x0a>;
				};

				data-pins {
					pins = "sdc2_data";
					bias-pull-up;
					drive-strength = <0x0a>;
				};
			};

			sdc2-off-state {
				phandle = <0x4a>;

				clk-pins {
					pins = "sdc2_clk";
					bias-disable;
					drive-strength = <0x02>;
				};

				cmd-pins {
					pins = "sdc2_cmd";
					bias-pull-up;
					drive-strength = <0x02>;
				};

				data-pins {
					pins = "sdc2_data";
					bias-pull-up;
					drive-strength = <0x02>;
				};
			};

			spi7-default-state {
				pins = "gpio24", "gpio25", "gpio26", "gpio27";
				function = "blsp_spi7";
				drive-strength = <0x06>;
				bias-disable;
				phandle = <0x87>;
			};

			spi7-sleep-state {
				pins = "gpio24", "gpio25", "gpio26", "gpio27";
				function = "blsp_spi7";
				drive-strength = <0x06>;
				bias-disable;
				phandle = <0x88>;
			};

			ts-active-state {
				pins = "gpio66", "gpio67";
				function = "gpio";
				drive-strength = <0x10>;
				bias-pull-up;
			};

			ts-int-sleep-state {
				pins = "gpio67";
				function = "gpio";
				drive-strength = <0x02>;
				bias-disable;
				phandle = <0x70>;
			};

			ts-reset-sleep-state {
				pins = "gpio66";
				function = "gpio";
				drive-strength = <0x02>;
				bias-pull-down;
				phandle = <0x71>;
			};

			touch-vdd-en-state {
				pins = "gpio15";
				function = "gpio";
				drive-strength = <0x02>;
				bias-disable;
				phandle = <0xac>;
			};

			r11t-ts-int-active-state {
				pins = "gpio67";
				function = "gpio";
				drive-strength = <0x08>;
				bias-pull-up;
				phandle = <0x6e>;
			};

			r11t-ts-reset-active-state {
				pins = "gpio66";
				function = "gpio";
				drive-strength = <0x08>;
				bias-disable;
				phandle = <0x6f>;
			};

			r11t-pri-mi2s-active-state {
				phandle = <0x9d>;

				clock-pins {
					pins = "gpio12", "gpio61";
					function = "pri_mi2s";
					drive-strength = <0x08>;
					bias-disable;
				};

				ws-pins {
					pins = "gpio13";
					function = "pri_mi2s_ws";
					drive-strength = <0x08>;
					bias-disable;
				};

				data-pins {
					pins = "gpio14";
					function = "pri_mi2s";
					drive-strength = <0x08>;
					bias-disable;
				};
			};

			r11t-sec-mi2s-active-state {
				phandle = <0x9e>;

				clock-pins {
					pins = "gpio24", "gpio25";
					function = "sec_mi2s";
					drive-strength = <0x08>;
					bias-disable;
				};

				data-pins {
					pins = "gpio26";
					function = "sec_mi2s";
					drive-strength = <0x08>;
					bias-disable;
				};
			};

			mdss-dsi-active-state {
				pins = "gpio53";
				function = "gpio";
				drive-strength = <0x08>;
				bias-disable;
				phandle = <0x62>;
			};

			mdss-dsi-suspend-state {
				pins = "gpio53";
				function = "gpio";
				drive-strength = <0x02>;
				bias-pull-down;
				phandle = <0x64>;
			};

			mdss-te-active-state {
				pins = "gpio59";
				function = "mdp_vsync";
				drive-strength = <0x02>;
				bias-pull-down;
				phandle = <0x63>;
			};

			mdss-te-suspend-state {
				pins = "gpio59";
				function = "mdp_vsync";
				drive-strength = <0x02>;
				bias-pull-down;
				phandle = <0x65>;
			};
		};

		ipa@14780000 {
			compatible = "qcom,ipa-lite-v2.6";
			reg = <0x14780000 0x47000>;
			clocks = <0x26 0x44>;
			interrupts = <0x00 0x14d 0x01 0x00 0x1b0 0x04>;
			interrupt-names = "ipa", "dma";
			interconnects = <0x29 0x00 0x2a 0x05 0x29 0x00 0x2b 0x0d 0x2c 0x00 0x2b 0x0a>;
			interconnect-names = "ipa-mem", "ipa-imem", "cpu-cfg";
			iommus = <0x2d 0x19c0 0x2d 0x19c2>;
			modem-remoteproc = <0x2e>;
			status = "okay";
		};

		remoteproc@4080000 {
			compatible = "qcom,sdm660-mss-pil";
			reg = <0x4080000 0x100 0x4180000 0x40>;
			reg-names = "qdsp6", "rmb";
			interrupts-extended = <0x01 0x00 0x1c0 0x01 0x2f 0x00 0x01 0x2f 0x01 0x01 0x2f 0x02 0x01 0x2f 0x03 0x01 0x2f 0x07 0x01>;
			interrupt-names = "wdog", "fatal", "ready", "handover", "stop-ack", "shutdown-ack";
			clocks = <0x25 0x40 0x25 0x18 0x25 0x2f 0x25 0x7c 0x25 0x44 0x25 0x42 0x26 0x08 0x26 0x00>;
			clock-names = "iface", "bus", "mem", "gpll0_mss", "snoc_axi", "mnoc_axi", "qdss", "xo";
			qcom,smem-states = <0x30 0x00>;
			qcom,smem-state-names = "stop";
			resets = <0x25 0x09>;
			reset-names = "mss_restart";
			qcom,halt-regs = <0x31 0x3000 0x5000 0x4000>;
			power-domains = <0x32 0x00 0x32 0x03>;
			power-domain-names = "cx", "mx";
			memory-region = <0x33 0x34 0x35>;
			status = "okay";
			firmware-name = "mba.mbn", "modem.mdt";
			phandle = <0x2e>;

			glink-edge {
				interrupts = <0x00 0x1c4 0x01>;
				label = "modem";
				qcom,remote-pid = <0x01>;
				mboxes = <0x1a 0x0f>;
			};
		};

		gpu@5000000 {
			compatible = "qcom,adreno-512.0", "qcom,adreno";
			reg = <0x5000000 0x40000>;
			reg-names = "kgsl_3d0_reg_memory";
			interrupts = <0x00 0x12c 0x04>;
			clocks = <0x25 0x37 0x36 0x08 0x25 0x16 0x25 0x36 0x36 0x06 0x36 0x07>;
			clock-names = "iface", "rbbmtimer", "mem", "mem_iface", "rbcpr", "core";
			power-domains = <0x32 0x03>;
			iommus = <0x37 0x00>;
			nvmem-cells = <0x38>;
			nvmem-cell-names = "speed_bin";
			interconnects = <0x2a 0x01 0x2a 0x05>;
			interconnect-names = "gfx-mem";
			operating-points-v2 = <0x39>;
			#cooling-cells = <0x02>;
			status = "okay";
			phandle = <0xa8>;

			opp-table {
				compatible = "operating-points-v2";
				phandle = <0x39>;

				opp-588000000 {
					opp-hz = <0x00 0x230c2b00>;
					opp-level = <0x100>;
					opp-peak-kBps = <0x2ee000>;
					opp-supported-hw = <0x70>;
				};

				opp-465000000 {
					opp-hz = <0x00 0x1bb75640>;
					opp-level = <0xc0>;
					opp-peak-kBps = <0x2990a0>;
					opp-supported-hw = <0x78>;
				};

				opp-370000000 {
					opp-hz = <0x00 0x160dc080>;
					opp-level = <0x80>;
					opp-peak-kBps = <0x2162e0>;
					opp-supported-hw = <0xff>;
				};

				opp-160000000 {
					opp-hz = <0x00 0x9896800>;
					opp-level = <0x30>;
					opp-peak-kBps = <0x124f80>;
					opp-supported-hw = <0xff>;
				};

				opp-19200000 {
					opp-hz = <0x00 0x124f800>;
					opp-level = <0x30>;
					opp-peak-kBps = <0x124f80>;
					opp-supported-hw = <0xff>;
				};

				opp-430000000 {
					opp-hz = <0x00 0x19a14780>;
					opp-level = <0xc0>;
					opp-peak-kBps = <0x2990a0>;
					opp-supported-hw = <0x04>;
				};

				opp-266000000 {
					opp-hz = <0x00 0xfdad680>;
					opp-level = <0x40>;
					opp-peak-kBps = <0x192580>;
					opp-supported-hw = <0xff>;
				};
			};

			zap-shader {
				memory-region = <0x3a>;
				firmware-name = "a512_zap.mbn";
			};
		};

		iommu@5040000 {
			compatible = "qcom,sdm630-smmu-v2", "qcom,adreno-smmu", "qcom,smmu-v2";
			reg = <0x5040000 0x10000>;
			power-domains = <0x36 0x01>;
			clocks = <0x25 0x37 0x25 0x16 0x25 0x36>;
			clock-names = "iface", "mem", "mem_iface";
			#global-interrupts = <0x02>;
			#iommu-cells = <0x01>;
			interrupts = <0x00 0xe5 0x04 0x00 0xe7 0x04 0x00 0x149 0x04 0x00 0x14a 0x04 0x00 0x14b 0x04 0x00 0x14c 0x04 0x00 0x74 0x04 0x00 0x75 0x04 0x00 0x15d 0x04 0x00 0x15e 0x04>;
			phandle = <0x37>;
		};

		clock-controller@5065000 {
			compatible = "qcom,gpucc-sdm660";
			#clock-cells = <0x01>;
			#reset-cells = <0x01>;
			#power-domain-cells = <0x01>;
			reg = <0x5065000 0x9038>;
			clocks = <0x23 0x25 0x38 0x25 0x39>;
			clock-names = "xo", "gcc_gpu_gpll0_clk", "gcc_gpu_gpll0_div_clk";
			phandle = <0x36>;
		};

		iommu@5100000 {
			compatible = "qcom,sdm630-smmu-v2", "qcom,smmu-v2";
			reg = <0x5100000 0x40000>;
			#iommu-cells = <0x01>;
			clocks = <0x25 0x83>;
			clock-names = "bus";
			power-domains = <0x25 0x05>;
			#global-interrupts = <0x02>;
			interrupts = <0x00 0xe5 0x04 0x00 0xe7 0x04 0x00 0xe2 0x04 0x00 0x189 0x04 0x00 0x18a 0x04 0x00 0x18b 0x04 0x00 0x18c 0x04 0x00 0x18d 0x04 0x00 0x18e 0x04 0x00 0x18f 0x04 0x00 0x190 0x04 0x00 0x191 0x04 0x00 0x192 0x04 0x00 0x193 0x04 0x00 0x89 0x04 0x00 0xe0 0x04 0x00 0xe1 0x04 0x00 0x136 0x04 0x00 0x194 0x04>;
			phandle = <0x94>;
		};

		sram@290000 {
			compatible = "qcom,rpm-stats";
			reg = <0x290000 0x10000>;
		};

		spmi@800f000 {
			compatible = "qcom,spmi-pmic-arb";
			reg = <0x800f000 0x1000 0x8400000 0x1000000 0x9400000 0x1000000 0xa400000 0x220000 0x800a000 0x3000>;
			reg-names = "core", "chnls", "obsrvr", "intr", "cnfg";
			interrupt-names = "periph_irq";
			interrupts = <0x00 0x146 0x04>;
			qcom,ee = <0x00>;
			qcom,channel = <0x00>;
			#address-cells = <0x02>;
			#size-cells = <0x00>;
			interrupt-controller;
			#interrupt-cells = <0x04>;

			pmic@0 {
				compatible = "qcom,pm660", "qcom,spmi-pmic";
				reg = <0x00 0x00>;
				#address-cells = <0x01>;
				#size-cells = <0x00>;

				rtc@6000 {
					compatible = "qcom,pm8941-rtc";
					reg = <0x6000 0x6100>;
					reg-names = "rtc", "alarm";
					interrupts = <0x00 0x61 0x01 0x01>;
				};

				pon@800 {
					compatible = "qcom,pm8998-pon";
					reg = <0x800>;
					mode-bootloader = <0x02>;
					mode-recovery = <0x01>;

					pwrkey {
						compatible = "qcom,pm8941-pwrkey";
						interrupts = <0x00 0x08 0x00 0x03>;
						debounce = <0x3d09>;
						bias-pull-up;
						linux,code = <0x74>;
						status = "okay";
					};

					resin {
						compatible = "qcom,pm8941-resin";
						interrupts = <0x00 0x08 0x01 0x03>;
						debounce = <0x3d09>;
						bias-pull-up;
						status = "okay";
						linux,code = <0x72>;
					};
				};

				charger@1000 {
					compatible = "qcom,pm660-charger";
					reg = <0x1000>;
					interrupts = <0x00 0x13 0x04 0x03 0x00 0x12 0x02 0x03 0x00 0x16 0x01 0x01 0x00 0x13 0x06 0x01>;
					interrupt-names = "usb-plugin", "bat-ov", "wdog-bark", "usbin-icl-change";
					io-channels = <0x3b 0x03 0x3b 0x04>;
					io-channel-names = "usbin_i", "usbin_v";
					/* Disabled like the reference build: the PM660 charger IC
					 * charges autonomously with stock-safe defaults; the
					 * mainline qcom_smbx driver wedges at status=Full with no
					 * input current and actively stops charging. */
					status = "disabled";
					monitored-battery = <0x3c>;
					phandle = <0x3e>;
				};

				temp-alarm@2400 {
					compatible = "qcom,spmi-temp-alarm";
					reg = <0x2400>;
					interrupts = <0x00 0x24 0x00 0x01>;
					io-channels = <0x3d 0x06>;
					io-channel-names = "thermal";
					#thermal-sensor-cells = <0x00>;
					phandle = <0xa9>;
				};

				adc@3100 {
					compatible = "qcom,spmi-adc-rev2";
					reg = <0x3100>;
					interrupts = <0x00 0x31 0x00 0x01>;
					#address-cells = <0x01>;
					#size-cells = <0x00>;
					#io-channel-cells = <0x01>;
					phandle = <0x3d>;

					channel@0 {
						reg = <0x00>;
						qcom,decimation = <0x400>;
						qcom,pre-scaling = <0x01 0x01>;
						label = "ref_gnd";
					};

					channel@1 {
						reg = <0x01>;
						qcom,decimation = <0x400>;
						qcom,pre-scaling = <0x01 0x01>;
						label = "vref_1p25";
					};

					channel@6 {
						reg = <0x06>;
						qcom,decimation = <0x400>;
						qcom,pre-scaling = <0x01 0x01>;
						label = "die_temp";
					};

					channel@4c {
						reg = <0x4c>;
						qcom,pre-scaling = <0x01 0x01>;
						qcom,decimation = <0x400>;
						qcom,hw-settle-time = <0xc8>;
						qcom,ratiometric;
						label = "xo_therm";
					};

					channel@4d {
						reg = <0x4d>;
						qcom,pre-scaling = <0x01 0x01>;
						qcom,decimation = <0x400>;
						qcom,hw-settle-time = <0xc8>;
						qcom,ratiometric;
						label = "msm_therm";
					};

					channel@4e {
						reg = <0x4e>;
						qcom,pre-scaling = <0x01 0x01>;
						qcom,decimation = <0x400>;
						qcom,hw-settle-time = <0xc8>;
						qcom,ratiometric;
						label = "emmc_therm";
					};

					channel@4f {
						reg = <0x4f>;
						qcom,pre-scaling = <0x01 0x01>;
						qcom,decimation = <0x400>;
						qcom,hw-settle-time = <0xc8>;
						qcom,ratiometric;
						label = "pa_therm0";
					};

					channel@50 {
						reg = <0x50>;
						qcom,pre-scaling = <0x01 0x01>;
						qcom,decimation = <0x400>;
						qcom,hw-settle-time = <0xc8>;
						qcom,ratiometric;
						label = "pa_therm1";
					};

					channel@51 {
						reg = <0x51>;
						qcom,pre-scaling = <0x01 0x01>;
						qcom,decimation = <0x400>;
						qcom,hw-settle-time = <0xc8>;
						qcom,ratiometric;
						label = "quiet_therm";
					};

					channel@83 {
						reg = <0x83>;
						qcom,decimation = <0x400>;
						qcom,pre-scaling = <0x01 0x03>;
						label = "vph_pwr";
					};

					channel@85 {
						reg = <0x85>;
						qcom,decimation = <0x400>;
						qcom,pre-scaling = <0x01 0x03>;
						label = "vcoin";
					};
				};

				battery@4000 {
					compatible = "qcom,pmi8998-fg";
					reg = <0x4000>;
					interrupts = <0x00 0x40 0x03 0x01>;
					interrupt-names = "soc-delta";
					status = "disabled";
					monitored-battery = <0x3c>;
					power-supplies = <0x3e>;
				};

				adc@4500 {
					compatible = "qcom,pm660-rradc";
					reg = <0x4500>;
					#io-channel-cells = <0x01>;
					status = "okay";
					phandle = <0x3b>;
				};

				gpio@c000 {
					compatible = "qcom,pm660-gpio", "qcom,spmi-gpio";
					reg = <0xc000>;
					gpio-controller;
					gpio-ranges = <0x3f 0x00 0x00 0x0d>;
					#gpio-cells = <0x02>;
					interrupt-controller;
					#interrupt-cells = <0x02>;
					phandle = <0x3f>;
				};

				usb-vbus-regulator@1500 {
					compatible = "qcom,pm660-vbus-reg";
					reg = <0x1500>;
					regulator-name = "usb_otg_vbus";
					regulator-min-microamp = <0x7a120>;
					regulator-max-microamp = <0x7a120>;
					phandle = <0x42>;
				};
			};

			pmic@1 {
				compatible = "qcom,pm660", "qcom,spmi-pmic";
				reg = <0x01 0x00>;
				#address-cells = <0x01>;
				#size-cells = <0x00>;

				vibrator@c000 {
					compatible = "qcom,pmi8998-haptics", "qcom,spmi-haptics";
					reg = <0xc000>;
					interrupts = <0x01 0xc0 0x00 0x03 0x01 0xc0 0x01 0x03>;
					interrupt-names = "short", "play";
					qcom,actuator-type = <0x00>;
					qcom,brake-pattern = <0x03 0x03 0x00 0x00>;
					qcom,play-mode = <0x01>;
					qcom,wave-play-rate-us = <0x1a0b>;
					qcom,wave-shape = <0x01>;
					status = "okay";
				};

				regulators {
					compatible = "qcom,pm660-regulators";
				};
			};

			pmic@2 {
				compatible = "qcom,pm660l", "qcom,spmi-pmic";
				reg = <0x02 0x00>;
				#address-cells = <0x01>;
				#size-cells = <0x00>;

				temp-alarm@2400 {
					compatible = "qcom,spmi-temp-alarm";
					reg = <0x2400>;
					interrupts = <0x02 0x24 0x00 0x03>;
					#thermal-sensor-cells = <0x00>;
					phandle = <0xaa>;
				};

				gpio@c000 {
					compatible = "qcom,pm660l-gpio", "qcom,spmi-gpio";
					reg = <0xc000>;
					gpio-controller;
					gpio-ranges = <0x40 0x00 0x00 0x0c>;
					#gpio-cells = <0x02>;
					interrupt-controller;
					#interrupt-cells = <0x02>;
					phandle = <0x40>;

					vol-up-default-state {
						pins = "gpio7";
						function = "normal";
						bias-pull-up;
						input-enable;
						qcom,drive-strength = <0x00>;
					};

					r11t-volume-keys-default-state {
						pins = "gpio5", "gpio8";
						function = "normal";
						bias-pull-up;
						input-enable;
						qcom,drive-strength = <0x00>;
						phandle = <0xab>;
					};
				};
			};

			pmic@3 {
				compatible = "qcom,pm660l", "qcom,spmi-pmic";
				reg = <0x03 0x00>;
				#address-cells = <0x01>;
				#size-cells = <0x00>;

				pwm {
					compatible = "qcom,pm660l-lpg";
					status = "okay";
					#address-cells = <0x01>;
					#size-cells = <0x00>;
					qcom,power-source = <0x01>;

					led@1 {
						reg = <0x01>;
						color = <0x00>;
						function = "status";
						default-state = "off";
					};
				};

				led-controller@d300 {
					compatible = "qcom,pm660l-flash-led", "qcom,spmi-flash-led";
					reg = <0xd300>;
					status = "okay";

					led-0 {
						function = "flash";
						color = <0x00>;
						led-sources = <0x01>;
						led-max-microamp = <0x186a0>;
						flash-max-microamp = <0xb71b0>;
						flash-max-timeout-us = <0x138800>;
					};
				};

				leds@d800 {
					compatible = "qcom,pm660l-wled";
					reg = <0xd800 0xd900>;
					interrupts = <0x03 0xd8 0x01 0x01 0x03 0xd8 0x02 0x01>;
					interrupt-names = "ovp", "short";
					label = "backlight";
					status = "okay";
					qcom,switching-freq = <0x320>;
					qcom,current-limit-microamp = <0x4e20>;
					qcom,num-strings = <0x02>;
				};

				audio-codec@f000 {
					compatible = "qcom,pm8916-wcd-analog-codec";
					reg = <0xf000>;
					interrupts = <0x03 0xf0 0x00 0x00 0x03 0xf0 0x01 0x00 0x03 0xf0 0x02 0x00 0x03 0xf0 0x03 0x00 0x03 0xf0 0x04 0x00 0x03 0xf0 0x05 0x00 0x03 0xf0 0x06 0x00 0x03 0xf0 0x07 0x00 0x03 0xf1 0x00 0x00 0x03 0xf1 0x01 0x00 0x03 0xf1 0x02 0x00 0x03 0xf1 0x03 0x00 0x03 0xf1 0x04 0x00 0x03 0xf1 0x05 0x00>;
					interrupt-names = "cdc_spk_cnp_int", "cdc_spk_clip_int", "cdc_spk_ocp_int", "mbhc_ins_rem_det1", "mbhc_but_rel_det", "mbhc_but_press_det", "mbhc_ins_rem_det", "mbhc_switch_int", "cdc_ear_ocp_int", "cdc_hphr_ocp_int", "cdc_hphl_ocp_det", "cdc_ear_cnp_int", "cdc_hphr_cnp_int", "cdc_hphl_cnp_int";
					qcom,hphl-jack-type-normally-open;
					qcom,gnd-jack-type-normally-open;
					qcom,mbhc-vthreshold-low = <0x3c 0x83 0xfd 0x1a9 0x1aa>;
					qcom,mbhc-vthreshold-high = <0x82 0x83 0xfd 0x1a9 0x1aa>;
					qcom,micbias2-ext-cap;
					#sound-dai-cells = <0x01>;
					status = "okay";
					vdd-cdc-io-supply = <0x20>;
					vdd-cdc-tx-rx-cx-supply = <0x20>;
					vdd-micbias-supply = <0x20>;
					qcom,micbias-lvl = <0xa8c>;
					qcom,mbhc-external-micbias;
					phandle = <0xa4>;
				};

				regulators {
					compatible = "qcom,pm660l-regulators";
				};

				oledb@e000 {
					compatible = "qcom,qpnp-oledb-regulator";
					reg = <0xe000>;
					regulator-name = "oledb";
					regulator-min-microvolt = <0x4c4b40>;
					regulator-max-microvolt = <0x7b98a0>;
					qcom,swire-control;
					qcom,ext-pin-control;
					phandle = <0x61>;
				};
			};
		};

		usb@a8f8800 {
			compatible = "qcom,sdm660-dwc3", "qcom,dwc3";
			reg = <0xa8f8800 0x400>;
			status = "okay";
			#address-cells = <0x01>;
			#size-cells = <0x01>;
			ranges;
			clocks = <0x25 0x31 0x25 0x5b 0x25 0x15 0x25 0x5d 0x25 0x5c>;
			clock-names = "cfg_noc", "core", "iface", "sleep", "mock_utmi";
			assigned-clocks = <0x25 0x5c 0x25 0x5b>;
			assigned-clock-rates = <0x124f800 0x7270e00>;
			interrupts = <0x00 0xb4 0x04 0x00 0x15b 0x04 0x00 0x85 0x04 0x00 0xf3 0x04>;
			interrupt-names = "pwr_event", "qusb2_phy", "hs_phy_irq", "ss_phy_irq";
			power-domains = <0x25 0x02>;
			resets = <0x25 0x07>;
			qcom,select-utmi-as-pipe-clk;

			usb@a800000 {
				compatible = "snps,dwc3";
				reg = <0xa800000 0xc8d0>;
				interrupts = <0x00 0x83 0x04>;
				snps,dis_u2_susphy_quirk;
				snps,dis_enblslpm_quirk;
				snps,parkmode-disable-ss-quirk;
				snps,dis-u1-entry-quirk;
				snps,dis-u2-entry-quirk;
				phys = <0x41>;
				phy-names = "usb2-phy";
				snps,hird-threshold = [00];
				maximum-speed = "high-speed";
				dr_mode = "otg";
				usb-role-switch;
				role-switch-default-mode = "peripheral";
				vbus-supply = <0x42>;
			};
		};

		phy@c010000 {
			compatible = "qcom,sdm660-qmp-usb3-phy";
			reg = <0xc010000 0x1000>;
			clocks = <0x25 0x5f 0x25 0x5e 0x25 0x61 0x25 0x60>;
			clock-names = "aux", "ref", "cfg_ahb", "pipe";
			clock-output-names = "usb3_phy_pipe_clk_src";
			#clock-cells = <0x00>;
			#phy-cells = <0x00>;
			resets = <0x25 0x04 0x25 0x05>;
			reset-names = "phy", "phy_phy";
			qcom,tcsr-reg = <0x31 0x6b244>;
			status = "disabled";
		};

		phy@c012000 {
			compatible = "qcom,sdm660-qusb2-phy";
			reg = <0xc012000 0x180>;
			#phy-cells = <0x00>;
			clocks = <0x25 0x61 0x25 0x81>;
			clock-names = "cfg_ahb", "ref";
			resets = <0x25 0x00>;
			nvmem-cells = <0x43>;
			status = "okay";
			vdd-supply = <0x44>;
			vdda-pll-supply = <0x45>;
			vdda-phy-dpdm-supply = <0x46>;
			phandle = <0x41>;
		};

		phy@c014000 {
			compatible = "qcom,sdm660-qusb2-phy";
			reg = <0xc014000 0x180>;
			#phy-cells = <0x00>;
			clocks = <0x25 0x61 0x25 0x82>;
			clock-names = "cfg_ahb", "ref";
			resets = <0x25 0x01>;
			nvmem-cells = <0x43>;
			status = "disabled";
			phandle = <0x51>;
		};

		mmc@c084000 {
			compatible = "qcom,sdm630-sdhci", "qcom,sdhci-msm-v5";
			reg = <0xc084000 0x1000>;
			reg-names = "hc";
			interrupts = <0x00 0x7d 0x04 0x00 0xdd 0x04>;
			interrupt-names = "hc_irq", "pwr_irq";
			bus-width = <0x04>;
			clocks = <0x25 0x4d 0x25 0x4e 0x23>;
			clock-names = "iface", "core", "xo";
			resets = <0x25 0x0b>;
			interconnects = <0x29 0x03 0x29 0x0a 0x2c 0x00 0x47 0x1c>;
			interconnect-names = "sdhc-ddr", "cpu-sdhc";
			operating-points-v2 = <0x48>;
			pinctrl-names = "default", "sleep";
			pinctrl-0 = <0x49>;
			pinctrl-1 = <0x4a>;
			power-domains = <0x32 0x00>;
			status = "disabled";

			opp-table {
				compatible = "operating-points-v2";
				phandle = <0x48>;

				opp-50000000 {
					opp-hz = <0x00 0x2faf080>;
					required-opps = <0x4b>;
					opp-peak-kBps = <0x30d40 0x222e0>;
					opp-avg-kBps = <0x1fe9e 0x208c8>;
				};

				opp-100000000 {
					opp-hz = <0x00 0x5f5e100>;
					required-opps = <0x16>;
					opp-peak-kBps = <0x3d090 0x27100>;
					opp-avg-kBps = <0x2fdee 0x249f0>;
				};

				opp-200000000 {
					opp-hz = <0x00 0xbebc200>;
					required-opps = <0x18>;
					opp-peak-kBps = <0x3e8000 0x3e8000>;
					opp-avg-kBps = <0x146cc2 0x146cc2>;
				};
			};
		};

		mmc@c0c4000 {
			compatible = "qcom,sdm630-sdhci", "qcom,sdhci-msm-v5";
			reg = <0xc0c4000 0x1000 0xc0c5000 0x1000 0xc0c8000 0x8000>;
			reg-names = "hc", "cqhci", "ice";
			interrupts = <0x00 0x6e 0x04 0x00 0x70 0x04>;
			interrupt-names = "hc_irq", "pwr_irq";
			clocks = <0x25 0x4a 0x25 0x4b 0x23 0x25 0x4c>;
			clock-names = "iface", "core", "xo", "ice";
			resets = <0x25 0x0a>;
			interconnects = <0x29 0x02 0x29 0x0a 0x2c 0x00 0x47 0x1b>;
			interconnect-names = "sdhc-ddr", "cpu-sdhc";
			operating-points-v2 = <0x4c>;
			pinctrl-names = "default", "sleep";
			pinctrl-0 = <0x4d>;
			pinctrl-1 = <0x4e>;
			power-domains = <0x32 0x00>;
			bus-width = <0x08>;
			non-removable;
			status = "okay";
			supports-cqe;
			mmc-hs200-1_8v;
			mmc-hs400-1_8v;
			mmc-hs400-enhanced-strobe;
			vmmc-supply = <0x4f>;
			vqmmc-supply = <0x50>;

			opp-table {
				compatible = "operating-points-v2";
				phandle = <0x4c>;

				opp-50000000 {
					opp-hz = <0x00 0x2faf080>;
					required-opps = <0x4b>;
					opp-peak-kBps = <0x30d40 0x222e0>;
					opp-avg-kBps = <0x1fe9e 0x208c8>;
				};

				opp-100000000 {
					opp-hz = <0x00 0x5f5e100>;
					required-opps = <0x16>;
					opp-peak-kBps = <0x3d090 0x27100>;
					opp-avg-kBps = <0x2fdee 0x249f0>;
				};

				opp-384000000 {
					opp-hz = <0x00 0x16e36000>;
					required-opps = <0x18>;
					opp-peak-kBps = <0x3e8000 0x3e8000>;
					opp-avg-kBps = <0x146cc2 0x146cc2>;
				};
			};
		};

		usb@c2f8800 {
			compatible = "qcom,sdm660-dwc3", "qcom,dwc3";
			reg = <0xc2f8800 0x400>;
			status = "disabled";
			#address-cells = <0x01>;
			#size-cells = <0x01>;
			ranges;
			clocks = <0x25 0x30 0x25 0x58 0x25 0x5a 0x25 0x59>;
			clock-names = "cfg_noc", "core", "sleep", "mock_utmi";
			assigned-clocks = <0x25 0x59 0x25 0x58>;
			assigned-clock-rates = <0x124f800 0x3938700>;
			interrupts = <0x00 0x90 0x04 0x00 0x15c 0x04 0x00 0x8b 0x04>;
			interrupt-names = "pwr_event", "qusb2_phy", "hs_phy_irq";
			qcom,select-utmi-as-pipe-clk;
			resets = <0x25 0x06>;

			usb@c200000 {
				compatible = "snps,dwc3";
				reg = <0xc200000 0xc8d0>;
				interrupts = <0x00 0x8f 0x04>;
				snps,dis_u2_susphy_quirk;
				snps,dis_enblslpm_quirk;
				snps,dis-u1-entry-quirk;
				snps,dis-u2-entry-quirk;
				maximum-speed = "high-speed";
				phys = <0x51>;
				phy-names = "usb2-phy";
				snps,hird-threshold = [00];
			};
		};

		clock-controller@c8c0000 {
			compatible = "qcom,mmcc-sdm660";
			reg = <0xc8c0000 0x40000>;
			#clock-cells = <0x01>;
			#reset-cells = <0x01>;
			#power-domain-cells = <0x01>;
			clock-names = "xo", "sleep_clk", "gpll0", "gpll0_div", "dsi0pll", "dsi0pllbyte", "dsi1pll", "dsi1pllbyte", "dp_link_2x_clk_divsel_five", "dp_vco_divided_clk_src_mux";
			clocks = <0x26 0x00 0x24 0x25 0x3c 0x25 0x3d 0x52 0x01 0x52 0x00 0x53 0x01 0x53 0x00 0x00 0x00>;
			phandle = <0x27>;
		};

		display-subsystem@c900000 {
			compatible = "qcom,mdss";
			reg = <0xc900000 0x1000 0xc9b0000 0x1040>;
			reg-names = "mdss_phys", "vbif_phys";
			power-domains = <0x27 0x02>;
			resets = <0x27 0x01>;
			clocks = <0x27 0x60 0x27 0x61 0x27 0x74 0x27 0x70>;
			clock-names = "iface", "bus", "vsync", "core";
			interrupts = <0x00 0x53 0x04>;
			interrupt-controller;
			#interrupt-cells = <0x01>;
			#address-cells = <0x01>;
			#size-cells = <0x01>;
			ranges;
			status = "okay";
			phandle = <0x54>;

			display-controller@c901000 {
				compatible = "qcom,sdm660-mdp5", "qcom,mdp5";
				reg = <0xc901000 0x89000>;
				reg-names = "mdp_phys";
				interrupt-parent = <0x54>;
				interrupts = <0x00>;
				assigned-clocks = <0x27 0x70 0x27 0x74>;
				assigned-clock-rates = <0x11e1a300 0x124f800>;
				clocks = <0x27 0x60 0x27 0x61 0x27 0x70 0x27 0x74>;
				clock-names = "iface", "bus", "core", "vsync";
				interconnects = <0x55 0x02 0x2a 0x05 0x55 0x03 0x2a 0x05 0x2c 0x00 0x55 0x11>;
				interconnect-names = "mdp0-mem", "mdp1-mem", "rotator-mem";
				iommus = <0x56 0x00>;
				operating-points-v2 = <0x57>;
				power-domains = <0x32 0x00>;

				ports {
					#address-cells = <0x01>;
					#size-cells = <0x00>;

					port@0 {
						reg = <0x00>;

						endpoint {
							remote-endpoint = <0x58>;
							phandle = <0x5d>;
						};
					};

					port@1 {
						reg = <0x01>;

						endpoint {
							remote-endpoint = <0x59>;
							phandle = <0x67>;
						};
					};
				};

				opp-table {
					compatible = "operating-points-v2";
					phandle = <0x57>;

					opp-150000000 {
						opp-hz = <0x00 0x8f0d180>;
						opp-peak-kBps = <0x4e200 0x4e200 0x12c00>;
						required-opps = <0x4b>;
					};

					opp-275000000 {
						opp-hz = <0x00 0x10642ac0>;
						opp-peak-kBps = <0x61a800 0x61a800 0x27100>;
						required-opps = <0x16>;
					};

					opp-300000000 {
						opp-hz = <0x00 0x11e1a300>;
						opp-peak-kBps = <0x61a800 0x61a800 0x2e630>;
						required-opps = <0x17>;
					};

					opp-330000000 {
						opp-hz = <0x00 0x13ab6680>;
						opp-peak-kBps = <0x61a800 0x61a800 0x3a980>;
						required-opps = <0x18>;
					};

					opp-412500000 {
						opp-hz = <0x00 0x18964020>;
						opp-peak-kBps = <0x61a800 0x61a800 0x4e200>;
						required-opps = <0x5a>;
					};
				};
			};

			dsi@c994000 {
				compatible = "qcom,sdm660-dsi-ctrl", "qcom,mdss-dsi-ctrl";
				reg = <0xc994000 0x400>;
				reg-names = "dsi_ctrl";
				operating-points-v2 = <0x5b>;
				power-domains = <0x32 0x00>;
				interrupt-parent = <0x54>;
				interrupts = <0x04>;
				assigned-clocks = <0x27 0x01 0x27 0x83>;
				assigned-clock-parents = <0x52 0x00 0x52 0x01>;
				clocks = <0x27 0x70 0x27 0x62 0x27 0x63 0x27 0x77 0x27 0x60 0x27 0x61 0x27 0x75 0x27 0x71 0x27 0x6d>;
				clock-names = "mdp_core", "byte", "byte_intf", "mnoc", "iface", "bus", "core_mmss", "pixel", "core";
				phys = <0x52>;
				status = "okay";
				#address-cells = <0x01>;
				#size-cells = <0x00>;
				vdd-supply = <0x44>;
				vdda-supply = <0x5c>;

				ports {
					#address-cells = <0x01>;
					#size-cells = <0x00>;

					port@0 {
						reg = <0x00>;

						endpoint {
							remote-endpoint = <0x5d>;
							phandle = <0x58>;
						};
					};

					port@1 {
						reg = <0x01>;

						endpoint {
							remote-endpoint = <0x5e>;
							data-lanes = <0x00 0x01 0x02 0x03>;
							phandle = <0x66>;
						};
					};
				};

				panel@0 {
					compatible = "samsung,s6e3fa3";
					reg = <0x00>;
					reset-gpios = <0x28 0x35 0x00>;
					rotation = <0xb4>;
					vddio-supply = <0x5f>;
					vdd-supply = <0x60>;
					oledb-supply = <0x61>;
					pinctrl-0 = <0x62 0x63>;
					pinctrl-1 = <0x64 0x65>;
					pinctrl-names = "default", "sleep";

					port {

						endpoint {
							remote-endpoint = <0x66>;
							phandle = <0x5e>;
						};
					};
				};
			};

			phy@c994400 {
				compatible = "qcom,dsi-phy-14nm-660";
				reg = <0xc994400 0x100 0xc994500 0x300 0xc994800 0x188>;
				reg-names = "dsi_phy", "dsi_phy_lane", "dsi_pll";
				#clock-cells = <0x01>;
				#phy-cells = <0x00>;
				clocks = <0x27 0x60 0x23>;
				clock-names = "iface", "ref";
				status = "okay";
				vcca-supply = <0x44>;
				phandle = <0x52>;
			};

			dsi@c996000 {
				compatible = "qcom,sdm660-dsi-ctrl", "qcom,mdss-dsi-ctrl";
				reg = <0xc996000 0x400>;
				reg-names = "dsi_ctrl";
				operating-points-v2 = <0x5b>;
				power-domains = <0x32 0x00>;
				interrupt-parent = <0x54>;
				interrupts = <0x05>;
				assigned-clocks = <0x27 0x02 0x27 0x84>;
				assigned-clock-parents = <0x53 0x00 0x53 0x01>;
				clocks = <0x27 0x70 0x27 0x65 0x27 0x66 0x27 0x77 0x27 0x60 0x27 0x61 0x27 0x75 0x27 0x72 0x27 0x6e>;
				clock-names = "mdp_core", "byte", "byte_intf", "mnoc", "iface", "bus", "core_mmss", "pixel", "core";
				phys = <0x53>;
				status = "disabled";

				ports {
					#address-cells = <0x01>;
					#size-cells = <0x00>;

					port@0 {
						reg = <0x00>;

						endpoint {
							remote-endpoint = <0x67>;
							phandle = <0x59>;
						};
					};

					port@1 {
						reg = <0x01>;

						endpoint {
						};
					};
				};
			};

			phy@c996400 {
				compatible = "qcom,dsi-phy-14nm-660";
				reg = <0xc996400 0x100 0xc996500 0x300 0xc996800 0x188>;
				reg-names = "dsi_phy", "dsi_phy_lane", "dsi_pll";
				#clock-cells = <0x01>;
				#phy-cells = <0x00>;
				clocks = <0x27 0x60 0x26 0x00>;
				clock-names = "iface", "ref";
				status = "disabled";
				phandle = <0x53>;
			};
		};

		dma-controller@c144000 {
			compatible = "qcom,bam-v1.7.0";
			reg = <0xc144000 0x1f000>;
			interrupts = <0x00 0xee 0x04>;
			clocks = <0x25 0x19>;
			clock-names = "bam_clk";
			#dma-cells = <0x01>;
			qcom,ee = <0x00>;
			qcom,controlled-remotely;
			num-channels = <0x12>;
			qcom,num-ees = <0x04>;
			phandle = <0x68>;
		};

		serial@c16f000 {
			compatible = "qcom,msm-uartdm-v1.4", "qcom,msm-uartdm";
			reg = <0xc16f000 0x200>;
			interrupts = <0x00 0x6b 0x04>;
			clocks = <0x25 0x22 0x25 0x19>;
			clock-names = "core", "iface";
			dmas = <0x68 0x00 0x68 0x01>;
			dma-names = "tx", "rx";
			pinctrl-names = "default", "sleep";
			pinctrl-0 = <0x69>;
			pinctrl-1 = <0x6a>;
			status = "disabled";
		};

		serial@c170000 {
			compatible = "qcom,msm-uartdm-v1.4", "qcom,msm-uartdm";
			reg = <0xc170000 0x1000>;
			interrupts = <0x00 0x6c 0x04>;
			clocks = <0x25 0x23 0x25 0x19>;
			clock-names = "core", "iface";
			dmas = <0x68 0x02 0x68 0x03>;
			dma-names = "tx", "rx";
			pinctrl-names = "default";
			pinctrl-0 = <0x6b>;
			status = "okay";
		};

		i2c@c175000 {
			compatible = "qcom,i2c-qup-v2.2.1";
			reg = <0xc175000 0x600>;
			interrupts = <0x00 0x5f 0x04>;
			clocks = <0x25 0x1a 0x25 0x19>;
			clock-names = "core", "iface";
			clock-frequency = <0x61a80>;
			dmas = <0x68 0x04 0x68 0x05>;
			dma-names = "tx", "rx";
			pinctrl-names = "default", "sleep";
			pinctrl-0 = <0x6c>;
			pinctrl-1 = <0x6d>;
			#address-cells = <0x01>;
			#size-cells = <0x00>;
			status = "okay";

			touchscreen@20 {
				compatible = "syna,rmi4-i2c";
				reg = <0x20>;
				#address-cells = <0x01>;
				#size-cells = <0x00>;
				interrupts-extended = <0x28 0x43 0x08>;
				pinctrl-0 = <0x6e 0x6f>;
				pinctrl-1 = <0x70 0x71>;
				pinctrl-names = "default", "sleep";
				vdd-supply = <0x72>;
				vio-supply = <0x73>;
				reset-gpios = <0x28 0x42 0x01>;
				syna,reset-delay-ms = <0x50>;
				syna,startup-delay-ms = <0x0a>;

				rmi4-f01@1 {
					reg = <0x01>;
					syna,nosleep-mode = <0x01>;
				};

				rmi4-f12@12 {
					reg = <0x12>;
					syna,sensor-type = <0x01>;
					touchscreen-inverted-x;
					touchscreen-inverted-y;
				};

				rmi4-f1a@1a {
					reg = <0x1a>;
					linux,keycodes = <0x8b 0x9e>;
				};
			};
		};

		i2c@c176000 {
			compatible = "qcom,i2c-qup-v2.2.1";
			reg = <0xc176000 0x600>;
			interrupts = <0x00 0x60 0x04>;
			clocks = <0x25 0x1c 0x25 0x19>;
			clock-names = "core", "iface";
			clock-frequency = <0x61a80>;
			dmas = <0x68 0x06 0x68 0x07>;
			dma-names = "tx", "rx";
			pinctrl-names = "default", "sleep";
			pinctrl-0 = <0x74>;
			pinctrl-1 = <0x75>;
			#address-cells = <0x01>;
			#size-cells = <0x00>;
			status = "okay";

			fuel-gauge@55 {
				compatible = "ti,bq27541";
				reg = <0x55>;
			};
		};

		i2c@c177000 {
			compatible = "qcom,i2c-qup-v2.2.1";
			reg = <0xc177000 0x600>;
			interrupts = <0x00 0x61 0x04>;
			clocks = <0x25 0x1e 0x25 0x19>;
			clock-names = "core", "iface";
			clock-frequency = <0x61a80>;
			dmas = <0x68 0x08 0x68 0x09>;
			dma-names = "tx", "rx";
			pinctrl-names = "default", "sleep";
			pinctrl-0 = <0x76>;
			pinctrl-1 = <0x77>;
			#address-cells = <0x01>;
			#size-cells = <0x00>;
			status = "disabled";
		};

		i2c@c178000 {
			compatible = "qcom,i2c-qup-v2.2.1";
			reg = <0xc178000 0x600>;
			interrupts = <0x00 0x62 0x04>;
			clocks = <0x25 0x20 0x25 0x19>;
			clock-names = "core", "iface";
			clock-frequency = <0x61a80>;
			dmas = <0x68 0x0a 0x68 0x0b>;
			dma-names = "tx", "rx";
			pinctrl-names = "default", "sleep";
			pinctrl-0 = <0x78>;
			pinctrl-1 = <0x79>;
			#address-cells = <0x01>;
			#size-cells = <0x00>;
			status = "disabled";
		};

		dma-controller@c184000 {
			compatible = "qcom,bam-v1.7.0";
			reg = <0xc184000 0x1f000>;
			interrupts = <0x00 0xef 0x04>;
			clocks = <0x25 0x24>;
			clock-names = "bam_clk";
			#dma-cells = <0x01>;
			qcom,ee = <0x00>;
			qcom,controlled-remotely;
			num-channels = <0x12>;
			qcom,num-ees = <0x04>;
			phandle = <0x7a>;
		};

		serial@c1af000 {
			compatible = "qcom,msm-uartdm-v1.4", "qcom,msm-uartdm";
			reg = <0xc1af000 0x200>;
			interrupts = <0x00 0x71 0x04>;
			clocks = <0x25 0x2d 0x25 0x24>;
			clock-names = "core", "iface";
			dmas = <0x7a 0x00 0x7a 0x01>;
			dma-names = "tx", "rx";
			pinctrl-names = "default", "sleep";
			pinctrl-0 = <0x7b>;
			pinctrl-1 = <0x7c>;
			status = "okay";

			bluetooth {
				compatible = "qcom,wcn3990-bt";
				vddxo-supply = <0x7d>;
				vddrf-supply = <0x7e>;
				vddch0-supply = <0x7f>;
				vddio-supply = <0x80>;
				max-speed = <0x30d400>;
			};
		};

		i2c@c1b5000 {
			compatible = "qcom,i2c-qup-v2.2.1";
			reg = <0xc1b5000 0x600>;
			interrupts = <0x00 0x65 0x04>;
			clocks = <0x25 0x25 0x25 0x24>;
			clock-names = "core", "iface";
			clock-frequency = <0x61a80>;
			dmas = <0x7a 0x04 0x7a 0x05>;
			dma-names = "tx", "rx";
			pinctrl-names = "default", "sleep";
			pinctrl-0 = <0x81>;
			pinctrl-1 = <0x82>;
			#address-cells = <0x01>;
			#size-cells = <0x00>;
			status = "disabled";
		};

		i2c@c1b6000 {
			compatible = "qcom,i2c-qup-v2.2.1";
			reg = <0xc1b6000 0x600>;
			interrupts = <0x00 0x66 0x04>;
			clocks = <0x25 0x27 0x25 0x24>;
			clock-names = "core", "iface";
			clock-frequency = <0x61a80>;
			dmas = <0x7a 0x06 0x7a 0x07>;
			dma-names = "tx", "rx";
			pinctrl-names = "default", "sleep";
			pinctrl-0 = <0x83>;
			pinctrl-1 = <0x84>;
			#address-cells = <0x01>;
			#size-cells = <0x00>;
			status = "okay";

			audio-codec@10 {
				compatible = "asahi-kasei,ak4376";
				reg = <0x10>;
				#sound-dai-cells = <0x00>;
				avdd-supply = <0x50>;
				tvdd-supply = <0x50>;
				pdn-gpios = <0x28 0x4c 0x00>;
				phandle = <0xa2>;
			};

			audio-codec@36 {
				compatible = "nxp,tfa9890";
				reg = <0x36>;
				#sound-dai-cells = <0x00>;
				vddd-supply = <0x80>;
				reset-gpios = <0x28 0x50 0x00>;
				phandle = <0xa3>;
			};
		};

		i2c@c1b7000 {
			compatible = "qcom,i2c-qup-v2.2.1";
			reg = <0xc1b7000 0x600>;
			interrupts = <0x00 0x67 0x04>;
			clocks = <0x25 0x29 0x25 0x24>;
			clock-names = "core", "iface";
			clock-frequency = <0x61a80>;
			dmas = <0x7a 0x08 0x7a 0x09>;
			dma-names = "tx", "rx";
			pinctrl-names = "default", "sleep";
			pinctrl-0 = <0x85>;
			pinctrl-1 = <0x86>;
			#address-cells = <0x01>;
			#size-cells = <0x00>;
			status = "disabled";
		};

		spi@c1b7000 {
			compatible = "qcom,spi-qup-v2.2.1";
			reg = <0xc1b7000 0x600>;
			interrupts = <0x00 0x67 0x04>;
			clocks = <0x25 0x2a 0x25 0x24>;
			clock-names = "core", "iface";
			dmas = <0x7a 0x08 0x7a 0x09>;
			dma-names = "tx", "rx";
			pinctrl-names = "default", "sleep";
			pinctrl-0 = <0x87>;
			pinctrl-1 = <0x88>;
			#address-cells = <0x01>;
			#size-cells = <0x00>;
			status = "disabled";
		};

		i2c@c1b8000 {
			compatible = "qcom,i2c-qup-v2.2.1";
			reg = <0xc1b8000 0x600>;
			interrupts = <0x00 0x68 0x04>;
			clocks = <0x25 0x2b 0x25 0x24>;
			clock-names = "core", "iface";
			clock-frequency = <0x61a80>;
			dmas = <0x7a 0x0a 0x7a 0x0b>;
			dma-names = "tx", "rx";
			pinctrl-names = "default", "sleep";
			pinctrl-0 = <0x89>;
			pinctrl-1 = <0x8a>;
			#address-cells = <0x01>;
			#size-cells = <0x00>;
			status = "disabled";
		};

		sram@146bf000 {
			compatible = "qcom,sdm630-imem", "syscon", "simple-mfd";
			reg = <0x146bf000 0x1000>;
			#address-cells = <0x01>;
			#size-cells = <0x01>;
			ranges = <0x00 0x146bf000 0x1000>;

			pil-reloc@94c {
				compatible = "qcom,pil-reloc-info";
				reg = <0x94c 0xc8>;
			};
		};

		camss@ca00020 {
			compatible = "qcom,sdm660-camss";
			reg = <0xca00020 0x10 0xca30000 0x100 0xca30400 0x100 0xca30800 0x100 0xca30c00 0x100 0xc824000 0x1000 0xca00120 0x04 0xc825000 0x1000 0xca00124 0x04 0xc826000 0x1000 0xca00128 0x04 0xca31000 0x500 0xca10000 0x1000 0xca14000 0x1000>;
			reg-names = "csi_clk_mux", "csid0", "csid1", "csid2", "csid3", "csiphy0", "csiphy0_clk_mux", "csiphy1", "csiphy1_clk_mux", "csiphy2", "csiphy2_clk_mux", "ispif", "vfe0", "vfe1";
			interrupts = <0x00 0x128 0x01 0x00 0x129 0x01 0x00 0x12a 0x01 0x00 0x12b 0x01 0x00 0x4e 0x01 0x00 0x4f 0x01 0x00 0x50 0x01 0x00 0x135 0x01 0x00 0x13a 0x01 0x00 0x13b 0x01>;
			interrupt-names = "csid0", "csid1", "csid2", "csid3", "csiphy0", "csiphy1", "csiphy2", "ispif", "vfe0", "vfe1";
			clocks = <0x27 0x27 0x27 0x2a 0x27 0x2b 0x27 0x2c 0x27 0x2d 0x27 0x32 0x27 0x33 0x27 0x2a 0x27 0x35 0x27 0x36 0x27 0x37 0x27 0x38 0x27 0x2b 0x27 0x3a 0x27 0x3b 0x27 0x3c 0x27 0x3d 0x27 0x2c 0x27 0x3f 0x27 0x40 0x27 0x41 0x27 0x42 0x27 0x2d 0x27 0x43 0x27 0x44 0x27 0x34 0x27 0x39 0x27 0x3e 0x27 0x5e 0x27 0x45 0x27 0x46 0x27 0x4c 0x27 0x7a 0x27 0x55 0x27 0x56 0x27 0x57 0x27 0x58 0x27 0x59 0x27 0x5a 0x27 0x5b 0x27 0x5c 0x27 0x5d>;
			clock-names = "ahb", "cphy_csid0", "cphy_csid1", "cphy_csid2", "cphy_csid3", "csi0_ahb", "csi0", "csi0_phy", "csi0_pix", "csi0_rdi", "csi1_ahb", "csi1", "csi1_phy", "csi1_pix", "csi1_rdi", "csi2_ahb", "csi2", "csi2_phy", "csi2_pix", "csi2_rdi", "csi3_ahb", "csi3", "csi3_phy", "csi3_pix", "csi3_rdi", "csiphy0_timer", "csiphy1_timer", "csiphy2_timer", "csiphy_ahb2crif", "csi_vfe0", "csi_vfe1", "ispif_ahb", "throttle_axi", "top_ahb", "vfe0_ahb", "vfe0", "vfe0_stream", "vfe1_ahb", "vfe1", "vfe1_stream", "vfe_ahb", "vfe_axi";
			interconnects = <0x55 0x05 0x2a 0x05>;
			interconnect-names = "vfe-mem";
			iommus = <0x56 0xc00 0x56 0xc01 0x56 0xc02 0x56 0xc03>;
			power-domains = <0x27 0x04 0x27 0x05>;
			status = "disabled";

			ports {
				#address-cells = <0x01>;
				#size-cells = <0x00>;
			};
		};

		cci@ca0c000 {
			compatible = "qcom,msm8996-cci";
			#address-cells = <0x01>;
			#size-cells = <0x00>;
			reg = <0xca0c000 0x1000>;
			interrupts = <0x00 0x127 0x01>;
			assigned-clocks = <0x27 0x28 0x27 0x29>;
			assigned-clock-rates = <0x4d0e900 0x23c3460>;
			clocks = <0x27 0x55 0x27 0x28 0x27 0x29 0x27 0x27>;
			clock-names = "camss_top_ahb", "cci_ahb", "cci", "camss_ahb";
			pinctrl-names = "default";
			pinctrl-0 = <0x8b 0x8c>;
			power-domains = <0x27 0x03>;
			status = "disabled";

			i2c-bus@0 {
				reg = <0x00>;
				clock-frequency = <0x61a80>;
				#address-cells = <0x01>;
				#size-cells = <0x00>;
			};

			i2c-bus@1 {
				reg = <0x01>;
				clock-frequency = <0x61a80>;
				#address-cells = <0x01>;
				#size-cells = <0x00>;
			};
		};

		video-codec@cc00000 {
			compatible = "qcom,sdm660-venus";
			reg = <0xcc00000 0xff000>;
			clocks = <0x27 0x81 0x27 0x7f 0x27 0x80 0x27 0x7e>;
			clock-names = "core", "iface", "bus", "bus_throttle";
			interconnects = <0x2c 0x00 0x55 0x0d 0x55 0x04 0x2a 0x05>;
			interconnect-names = "cpu-cfg", "video-mem";
			interrupts = <0x00 0x11f 0x04>;
			iommus = <0x56 0x400 0x56 0x401 0x56 0x40a 0x56 0x407 0x56 0x40e 0x56 0x40f 0x56 0x408 0x56 0x409 0x56 0x40b 0x56 0x40c 0x56 0x40d 0x56 0x410 0x56 0x421 0x56 0x428 0x56 0x429 0x56 0x42b 0x56 0x42c 0x56 0x42d 0x56 0x411 0x56 0x431>;
			memory-region = <0x8d>;
			power-domains = <0x27 0x00>;
			status = "disabled";

			video-decoder {
				compatible = "venus-decoder";
				clocks = <0x27 0x82>;
				clock-names = "vcodec0_core";
				power-domains = <0x27 0x01>;
			};

			video-encoder {
				compatible = "venus-encoder";
				clocks = <0x27 0x82>;
				clock-names = "vcodec0_core";
				power-domains = <0x27 0x01>;
			};
		};

		iommu@cd00000 {
			compatible = "qcom,sdm630-smmu-v2", "qcom,smmu-v2";
			reg = <0xcd00000 0x40000>;
			clocks = <0x27 0x77 0x27 0x25 0x27 0x26>;
			clock-names = "iface-mm", "iface-smmu", "bus-smmu";
			#global-interrupts = <0x02>;
			#iommu-cells = <0x01>;
			interrupts = <0x00 0xe5 0x04 0x00 0xe7 0x04 0x00 0x107 0x04 0x00 0x10a 0x04 0x00 0x10b 0x04 0x00 0x10c 0x04 0x00 0xf4 0x04 0x00 0xf5 0x04 0x00 0xf7 0x04 0x00 0xf8 0x04 0x00 0xf9 0x04 0x00 0xfa 0x04 0x00 0xfb 0x04 0x00 0xfc 0x04 0x00 0xfd 0x04 0x00 0xfe 0x04 0x00 0xff 0x04 0x00 0x100 0x04 0x00 0x104 0x04 0x00 0x105 0x04 0x00 0x106 0x04 0x00 0x110 0x04 0x00 0x111 0x04 0x00 0x112 0x04 0x00 0x113 0x04 0x00 0x114 0x04>;
			status = "okay";
			phandle = <0x56>;
		};

		pinctrl@15070000 {
			compatible = "qcom,sdm660-lpass-lpi-pinctrl";
			reg = <0x15070000 0x20000>;
			gpio-controller;
			#gpio-cells = <0x02>;
			gpio-ranges = <0x8e 0x00 0x00 0x20>;
			phandle = <0x8e>;

			cdc-pdm-default-state {
				phandle = <0x9b>;

				clk-pins {
					pins = "gpio18";
					function = "pdm_clk";
					drive-strength = <0x08>;
					output-high;
				};

				sync-pins {
					pins = "gpio19";
					function = "pdm_sync";
					drive-strength = <0x04>;
					output-high;
				};

				tx-pins {
					pins = "gpio20";
					function = "pdm_tx";
					drive-strength = <0x08>;
				};

				rx-pins {
					pins = "gpio21", "gpio23", "gpio25";
					function = "pdm_rx";
					drive-strength = <0x04>;
					output-high;
				};
			};

			cdc-comp-default-state {
				pins = "gpio22", "gpio24";
				function = "comp_rx";
				drive-strength = <0x08>;
			};

			cdc-dmic-default-state {
				phandle = <0x9c>;

				dmic1-clk-pins {
					pins = "gpio26";
					function = "dmic1_clk";
					drive-strength = <0x08>;
					output-high;
				};

				dmic1-data-pins {
					pins = "gpio27";
					function = "dmic1_data";
					drive-strength = <0x08>;
					output-high;
				};

				dmic2-clk-pins {
					pins = "gpio28";
					function = "dmic2_clk";
					drive-strength = <0x08>;
					input-enable;
				};

				dmic2-data-pins {
					pins = "gpio29";
					function = "dmic2_data";
					drive-strength = <0x08>;
					input-enable;
				};
			};
		};

		audio-codec@152c0000 {
			compatible = "qcom,msm8916-wcd-digital-codec";
			reg = <0x152c0000 0x400>;
			clocks = <0x8f 0x90 0x33 0x01>;
			clock-names = "ahbix-clk", "mclk";
			assigned-clocks = <0x90 0x33 0x01>;
			assigned-clock-rates = <0x927c00>;
			sound-name-prefix = "Digital";
			#sound-dai-cells = <0x01>;
			status = "okay";
			phandle = <0xa5>;
		};

		remoteproc@15700000 {
			compatible = "qcom,sdm660-adsp-pas";
			reg = <0x15700000 0x4040>;
			interrupts-extended = <0x01 0x00 0xa2 0x01 0x91 0x00 0x01 0x91 0x01 0x01 0x91 0x02 0x01 0x91 0x03 0x01>;
			interrupt-names = "wdog", "fatal", "ready", "handover", "stop-ack";
			clocks = <0x26 0x00>;
			clock-names = "xo";
			memory-region = <0x92>;
			power-domains = <0x32 0x00>;
			power-domain-names = "cx";
			qcom,smem-states = <0x93 0x00>;
			qcom,smem-state-names = "stop";
			firmware-name = "adsp.mdt";

			glink-edge {
				interrupts = <0x00 0x9d 0x01>;
				label = "lpass";
				mboxes = <0x1a 0x09>;
				qcom,remote-pid = <0x02>;

				apr {
					compatible = "qcom,apr-v2";
					qcom,glink-channels = "apr_audio_svc";
					qcom,domain = <0x04>;
					#address-cells = <0x01>;
					#size-cells = <0x00>;

					service@3 {
						reg = <0x03>;
						compatible = "qcom,q6core";
					};

					service@4 {
						compatible = "qcom,q6afe";
						reg = <0x04>;
						qcom,protection-domain = "avs/audio", "msm/adsp/audio_pd";

						clock-controller {
							compatible = "qcom,q6afe-clocks";
							#clock-cells = <0x02>;
							phandle = <0x90>;
						};

						dais {
							compatible = "qcom,q6afe-dais";
							#address-cells = <0x01>;
							#size-cells = <0x00>;
							#sound-dai-cells = <0x01>;
							phandle = <0xa0>;

							dai@16 {
								reg = <0x10>;
								qcom,sd-lines = <0x00>;
							};

							dai@18 {
								reg = <0x12>;
								qcom,sd-lines = <0x00>;
							};

							dai@81 {
								reg = <0x89>;
								qcom,sd-lines = <0x00 0x01>;
							};

							dai@88 {
								reg = <0x90>;
								qcom,sd-lines = <0x00 0x01>;
							};
						};
					};

					service@7 {
						compatible = "qcom,q6asm";
						reg = <0x07>;
						qcom,protection-domain = "avs/audio", "msm/adsp/audio_pd";

						dais {
							compatible = "qcom,q6asm-dais";
							#address-cells = <0x01>;
							#size-cells = <0x00>;
							#sound-dai-cells = <0x01>;
							iommus = <0x94 0x01>;
							phandle = <0x9f>;

							dai@0 {
								reg = <0x00>;
							};

							dai@1 {
								reg = <0x01>;
							};
						};
					};

					service@8 {
						compatible = "qcom,q6adm";
						reg = <0x08>;
						qcom,protection-domain = "avs/audio", "msm/adsp/audio_pd";

						routing {
							compatible = "qcom,q6adm-routing";
							#sound-dai-cells = <0x00>;
							phandle = <0xa1>;
						};
					};
				};

				fastrpc {
					compatible = "qcom,fastrpc";
					qcom,glink-channels = "fastrpcglink-apps-dsp";
					label = "adsp";
					qcom,non-secure-domain;
					#address-cells = <0x01>;
					#size-cells = <0x00>;

					compute-cb@1 {
						compatible = "qcom,fastrpc-compute-cb";
						reg = <0x01>;
						iommus = <0x94 0x03>;
					};

					compute-cb@2 {
						compatible = "qcom,fastrpc-compute-cb";
						reg = <0x02>;
						iommus = <0x94 0x07>;
					};

					compute-cb@3 {
						compatible = "qcom,fastrpc-compute-cb";
						reg = <0x03>;
						iommus = <0x94 0x08>;
					};

					compute-cb@4 {
						compatible = "qcom,fastrpc-compute-cb";
						reg = <0x04>;
						iommus = <0x94 0x09>;
					};
				};
			};
		};

		interconnect@17900000 {
			compatible = "qcom,sdm660-gnoc";
			reg = <0x17900000 0xe000>;
			#interconnect-cells = <0x01>;
			phandle = <0x2c>;
		};

		mailbox@17911000 {
			compatible = "qcom,sdm660-apcs-hmss-global", "qcom,msm8994-apcs-kpss-global";
			reg = <0x17911000 0x1000>;
			#mbox-cells = <0x01>;
			phandle = <0x1a>;
		};

		timer@17920000 {
			#address-cells = <0x01>;
			#size-cells = <0x01>;
			ranges;
			compatible = "arm,armv7-timer-mem";
			reg = <0x17920000 0x1000>;
			clock-frequency = <0x124f800>;

			frame@17921000 {
				frame-number = <0x00>;
				interrupts = <0x00 0x08 0x04 0x00 0x07 0x04>;
				reg = <0x17921000 0x1000 0x17922000 0x1000>;
			};

			frame@17923000 {
				frame-number = <0x01>;
				interrupts = <0x00 0x09 0x04>;
				reg = <0x17923000 0x1000>;
				status = "disabled";
			};

			frame@17924000 {
				frame-number = <0x02>;
				interrupts = <0x00 0x0a 0x04>;
				reg = <0x17924000 0x1000>;
				status = "disabled";
			};

			frame@17925000 {
				frame-number = <0x03>;
				interrupts = <0x00 0x0b 0x04>;
				reg = <0x17925000 0x1000>;
				status = "disabled";
			};

			frame@17926000 {
				frame-number = <0x04>;
				interrupts = <0x00 0x0c 0x04>;
				reg = <0x17926000 0x1000>;
				status = "disabled";
			};

			frame@17927000 {
				frame-number = <0x05>;
				interrupts = <0x00 0x0d 0x04>;
				reg = <0x17927000 0x1000>;
				status = "disabled";
			};

			frame@17928000 {
				frame-number = <0x06>;
				interrupts = <0x00 0x0e 0x04>;
				reg = <0x17928000 0x1000>;
				status = "disabled";
			};
		};

		interrupt-controller@17a00000 {
			compatible = "arm,gic-v3";
			reg = <0x17a00000 0x10000 0x17b00000 0x100000>;
			#interrupt-cells = <0x03>;
			#address-cells = <0x01>;
			#size-cells = <0x01>;
			ranges;
			interrupt-controller;
			#redistributor-regions = <0x01>;
			redistributor-stride = <0x00 0x20000>;
			interrupts = <0x01 0x09 0x04>;
			phandle = <0x01>;
		};

		wifi@18800000 {
			compatible = "qcom,wcn3990-wifi";
			reg = <0x18800000 0x800000>;
			reg-names = "membase";
			memory-region = <0x95>;
			clocks = <0x26 0x16>;
			clock-names = "cxo_ref_clk_pin";
			interrupts = <0x00 0x19d 0x04 0x00 0x19e 0x04 0x00 0x19f 0x04 0x00 0x1a0 0x04 0x00 0x1a1 0x04 0x00 0x1a2 0x04 0x00 0x1a4 0x04 0x00 0x1a5 0x04 0x00 0x1a6 0x04 0x00 0x1a7 0x04 0x00 0x1a8 0x04 0x00 0x1a9 0x04>;
			iommus = <0x2d 0x1a00 0x2d 0x1a01>;
			qcom,snoc-host-cap-8bit-quirk;
			qcom,no-msa-ready-indicator;
			status = "okay";
			vdd-0.8-cx-mx-supply = <0x96>;
			vdd-1.8-xo-supply = <0x7d>;
			vdd-1.3-rfa-supply = <0x7e>;
			vdd-3.3-ch0-supply = <0x7f>;
		};

		iommu@5180000 {
			compatible = "qcom,sdm630-smmu-v2", "qcom,smmu-v2";
			reg = <0x5180000 0x40000>;
			#iommu-cells = <0x01>;
			#global-interrupts = <0x02>;
			interrupts = <0x00 0xe5 0x04 0x00 0xe7 0x04 0x00 0x215 0x04 0x00 0x216 0x04 0x00 0x217 0x04 0x00 0x218 0x04 0x00 0x219 0x04 0x00 0x21a 0x04 0x00 0x21b 0x04 0x00 0x21c 0x04 0x00 0x21d 0x04 0x00 0x21e 0x04 0x00 0x21f 0x04 0x00 0x220 0x04 0x00 0x221 0x04 0x00 0x222 0x04 0x00 0x223 0x04 0x00 0x224 0x04 0x00 0x225 0x04>;
			clocks = <0x25 0x84>;
			clock-names = "bus";
			power-domains = <0x25 0x03>;
			phandle = <0x9a>;
		};

		remoteproc@1a300000 {
			compatible = "qcom,sdm660-cdsp-pas";
			reg = <0x1a300000 0x100>;
			interrupts-extended = <0x01 0x00 0x206 0x01 0x97 0x00 0x01 0x97 0x01 0x01 0x97 0x02 0x01 0x97 0x03 0x01>;
			interrupt-names = "wdog", "fatal", "ready", "handover", "stop-ack";
			clocks = <0x26 0x00>;
			clock-names = "xo";
			memory-region = <0x98>;
			power-domains = <0x32 0x00>;
			power-domain-names = "cx";
			qcom,smem-states = <0x99 0x00>;
			qcom,smem-state-names = "stop";

			glink-edge {
				interrupts = <0x00 0x201 0x01>;
				label = "cdsp";
				mboxes = <0x1a 0x1d>;
				qcom,remote-pid = <0x05>;

				fastrpc {
					compatible = "qcom,fastrpc";
					qcom,glink-channels = "fastrpcglink-apps-dsp";
					label = "cdsp";
					#address-cells = <0x01>;
					#size-cells = <0x00>;

					compute-cb@5 {
						compatible = "qcom,fastrpc-compute-cb";
						reg = <0x05>;
						iommus = <0x9a 0x03>;
					};

					compute-cb@6 {
						compatible = "qcom,fastrpc-compute-cb";
						reg = <0x06>;
						iommus = <0x9a 0x04>;
					};

					compute-cb@7 {
						compatible = "qcom,fastrpc-compute-cb";
						reg = <0x07>;
						iommus = <0x9a 0x05>;
					};

					compute-cb@8 {
						compatible = "qcom,fastrpc-compute-cb";
						reg = <0x08>;
						iommus = <0x9a 0x06>;
					};

					compute-cb@9 {
						compatible = "qcom,fastrpc-compute-cb";
						reg = <0x09>;
						iommus = <0x9a 0x07>;
					};

					compute-cb@10 {
						compatible = "qcom,fastrpc-compute-cb";
						reg = <0x0a>;
						iommus = <0x9a 0x08>;
					};

					compute-cb@11 {
						compatible = "qcom,fastrpc-compute-cb";
						reg = <0x0b>;
						iommus = <0x9a 0x09>;
					};

					compute-cb@12 {
						compatible = "qcom,fastrpc-compute-cb";
						reg = <0x0c>;
						iommus = <0x9a 0x0a>;
					};

					compute-cb@13 {
						compatible = "qcom,fastrpc-compute-cb";
						reg = <0x0d>;
						iommus = <0x9a 0x0b>;
					};
				};
			};
		};
	};

	sound {
		compatible = "qcom,sdm660-internal-sndcard";
		model = "OPPO R11T";
		pinctrl-0 = <0x9b 0x9c 0x9d 0x9e>;
		pinctrl-names = "default";
		audio-routing = "RX_BIAS", "Digital MCLK", "INT_LDO_H", "Digital MCLK", "Digital RX_I2S_CLK", "Digital MCLK", "Digital TX_I2S_CLK", "Digital MCLK", "Digital ADC1", "ADC1", "Digital ADC2", "ADC2", "Digital ADC3", "ADC3", "PDM_RX1", "Digital PDM_RX1", "PDM_RX2", "Digital PDM_RX2", "PDM_RX3", "Digital PDM_RX3", "Digital LPASS_PDM_TX", "PDM_TX", "Headphone Jack", "HPH_L", "Headphone Jack", "HPH_R", "Headphone Jack", "HPL", "Headphone Jack", "HPR", "Speaker", "OUT", "AMIC1", "MIC BIAS External1", "AMIC2", "MIC BIAS External2", "Mic Jack", "MIC BIAS External2";

		mm1-dai-link {
			link-name = "MultiMedia1";

			cpu {
				sound-dai = <0x9f 0x00>;
			};
		};

		mm2-dai-link {
			link-name = "MultiMedia2";

			cpu {
				sound-dai = <0x9f 0x01>;
			};
		};

		pri-mi2s-dai-link {
			link-name = "Primary MI2S Playback";

			cpu {
				sound-dai = <0xa0 0x10>;
			};

			platform {
				sound-dai = <0xa1>;
			};

			codec {
				sound-dai = <0xa2>;
			};
		};

		sec-mi2s-dai-link {
			link-name = "Secondary MI2S Playback";

			cpu {
				sound-dai = <0xa0 0x12>;
			};

			platform {
				sound-dai = <0xa1>;
			};

			codec {
				sound-dai = <0xa3>;
			};
		};

		int0-mi2s-dai-link {
			link-name = "Internal MI2S Playback";

			cpu {
				sound-dai = <0xa0 0x89>;
			};

			platform {
				sound-dai = <0xa1>;
			};

			codec {
				sound-dai = <0xa4 0x00 0xa5 0x00>;
			};
		};

		int3-mi2s-dai-link {
			link-name = "Internal MI2S Capture";

			cpu {
				sound-dai = <0xa0 0x90>;
			};

			platform {
				sound-dai = <0xa1>;
			};

			codec {
				sound-dai = <0xa4 0x01 0xa5 0x01>;
			};
		};
	};

	thermal-zones {

		aoss-thermal {
			polling-delay-passive = <0xfa>;
			thermal-sensors = <0xa6 0x00>;

			trips {

				trip-point0 {
					temperature = <0x19a28>;
					hysteresis = <0x3e8>;
					type = "hot";
				};
			};
		};

		cpuss0-thermal {
			polling-delay-passive = <0xfa>;
			thermal-sensors = <0xa6 0x01>;

			trips {

				trip-point0 {
					temperature = <0x1e848>;
					hysteresis = <0x3e8>;
					type = "hot";
				};
			};
		};

		cpuss1-thermal {
			polling-delay-passive = <0xfa>;
			thermal-sensors = <0xa6 0x02>;

			trips {

				trip-point0 {
					temperature = <0x1e848>;
					hysteresis = <0x3e8>;
					type = "hot";
				};
			};
		};

		cpu0-thermal {
			polling-delay-passive = <0xfa>;
			thermal-sensors = <0xa6 0x03>;

			trips {

				trip-point0 {
					temperature = <0x11170>;
					hysteresis = <0x3e8>;
					type = "passive";
				};

				cpu-crit {
					temperature = <0x1adb0>;
					hysteresis = <0x3e8>;
					type = "critical";
				};
			};
		};

		cpu1-thermal {
			polling-delay-passive = <0xfa>;
			thermal-sensors = <0xa6 0x04>;

			trips {

				trip-point0 {
					temperature = <0x11170>;
					hysteresis = <0x3e8>;
					type = "passive";
				};

				cpu-crit {
					temperature = <0x1adb0>;
					hysteresis = <0x3e8>;
					type = "critical";
				};
			};
		};

		cpu2-thermal {
			polling-delay-passive = <0xfa>;
			thermal-sensors = <0xa6 0x05>;

			trips {

				trip-point0 {
					temperature = <0x11170>;
					hysteresis = <0x3e8>;
					type = "passive";
				};

				cpu-crit {
					temperature = <0x1adb0>;
					hysteresis = <0x3e8>;
					type = "critical";
				};
			};
		};

		cpu3-thermal {
			polling-delay-passive = <0xfa>;
			thermal-sensors = <0xa6 0x06>;

			trips {

				trip-point0 {
					temperature = <0x11170>;
					hysteresis = <0x3e8>;
					type = "passive";
				};

				cpu-crit {
					temperature = <0x1adb0>;
					hysteresis = <0x3e8>;
					type = "critical";
				};
			};
		};

		pwr-cluster-thermal {
			polling-delay-passive = <0xfa>;
			thermal-sensors = <0xa6 0x07>;

			trips {

				trip-point0 {
					temperature = <0x11170>;
					hysteresis = <0x3e8>;
					type = "passive";
				};

				cpu-crit {
					temperature = <0x1adb0>;
					hysteresis = <0x3e8>;
					type = "critical";
				};
			};
		};

		gpu-thermal {
			polling-delay-passive = <0xfa>;
			thermal-sensors = <0xa6 0x08>;

			cooling-maps {

				map0 {
					trip = <0xa7>;
					cooling-device = <0xa8 0xffffffff 0xffffffff>;
				};
			};

			trips {

				trip-point0 {
					temperature = <0x14c08>;
					hysteresis = <0x3e8>;
					type = "passive";
					phandle = <0xa7>;
				};

				trip-point1 {
					temperature = <0x15f90>;
					hysteresis = <0x3e8>;
					type = "hot";
				};

				trip-point2 {
					temperature = <0x1adb0>;
					hysteresis = <0x3e8>;
					type = "critical";
				};
			};
		};

		pm660-thermal {
			polling-delay-passive = <0xfa>;
			thermal-sensors = <0xa9>;

			trips {

				pm660-alert0 {
					temperature = <0x17318>;
					hysteresis = <0x7d0>;
					type = "passive";
				};

				pm660-crit {
					temperature = <0x1e848>;
					hysteresis = <0x7d0>;
					type = "critical";
				};
			};
		};

		pm660l-thermal {
			polling-delay-passive = <0xfa>;
			thermal-sensors = <0xaa>;

			trips {

				pm660l-alert0 {
					temperature = <0x17318>;
					hysteresis = <0x7d0>;
					type = "passive";
				};

				pm660l-crit {
					temperature = <0x1e848>;
					hysteresis = <0x7d0>;
					type = "critical";
				};
			};
		};
	};

	timer {
		compatible = "arm,armv8-timer";
		interrupts = <0x01 0x01 0xf08 0x01 0x02 0xf08 0x01 0x03 0xf08 0x01 0x00 0xf08>;
	};

	smp2p-cdsp {
		compatible = "qcom,smp2p";
		qcom,smem = <0x5e 0x1b0>;
		interrupts = <0x00 0x202 0x01>;
		mboxes = <0x1a 0x1e>;
		qcom,local-pid = <0x00>;
		qcom,remote-pid = <0x05>;

		master-kernel {
			qcom,entry-name = "master-kernel";
			#qcom,smem-state-cells = <0x01>;
			phandle = <0x99>;
		};

		slave-kernel {
			qcom,entry-name = "slave-kernel";
			interrupt-controller;
			#interrupt-cells = <0x02>;
			phandle = <0x97>;
		};
	};

	battery {
		compatible = "simple-battery";
		charge-full-design-microamp-hours = <0x312220>;
		voltage-min-design-microvolt = <0x33e140>;
		voltage-max-design-microvolt = <0x426030>;
		constant-charge-current-max-microamp = <0x16e360>;
		phandle = <0x3c>;
	};

	vph-pwr-regulator {
		compatible = "regulator-fixed";
		regulator-name = "vph_pwr";
		regulator-min-microvolt = <0x387520>;
		regulator-max-microvolt = <0x387520>;
		regulator-always-on;
		regulator-boot-on;
		phandle = <0x1c>;
	};

	lcdb-regulator {
		compatible = "regulator-fixed";
		regulator-name = "lcdb";
		regulator-min-microvolt = <0x53ec60>;
		regulator-max-microvolt = <0x53ec60>;
		regulator-always-on;
		regulator-boot-on;
	};

	disp-vddts-regulator {
		compatible = "regulator-fixed";
		regulator-name = "disp_vddts_vreg";
		regulator-min-microvolt = <0x2ab980>;
		regulator-max-microvolt = <0x2ab980>;
		startup-delay-us = <0xfa0>;
		enable-active-high;
		regulator-boot-on;
		gpio = <0x28 0x49 0x00>;
	};

	gpio-keys {
		compatible = "gpio-keys";
		pinctrl-0 = <0xab>;
		pinctrl-names = "default";

		key-volume-up {
			label = "Volume Up";
			gpios = <0x40 0x08 0x01>;
			linux,code = <0x73>;
			debounce-interval = <0x0f>;
			wakeup-source;
		};

		key-volume-down {
			label = "Volume Down";
			gpios = <0x40 0x05 0x01>;
			linux,code = <0x72>;
			debounce-interval = <0x0f>;
			wakeup-source;
		};
	};

	extcon-usb {
		compatible = "linux,extcon-usb-gpio";
		id-gpios = <0x28 0x3a 0x00>;
	};

	regulator-touch-vdd {
		compatible = "regulator-fixed";
		regulator-name = "touchpanel_vdd";
		regulator-min-microvolt = <0x2ab980>;
		regulator-max-microvolt = <0x2ab980>;
		gpio = <0x28 0x0f 0x00>;
		enable-active-high;
		pinctrl-0 = <0xac>;
		pinctrl-names = "default";
		phandle = <0x72>;
	};

	memshare {
		compatible = "oppo,r11t-memshare";
	};
};
